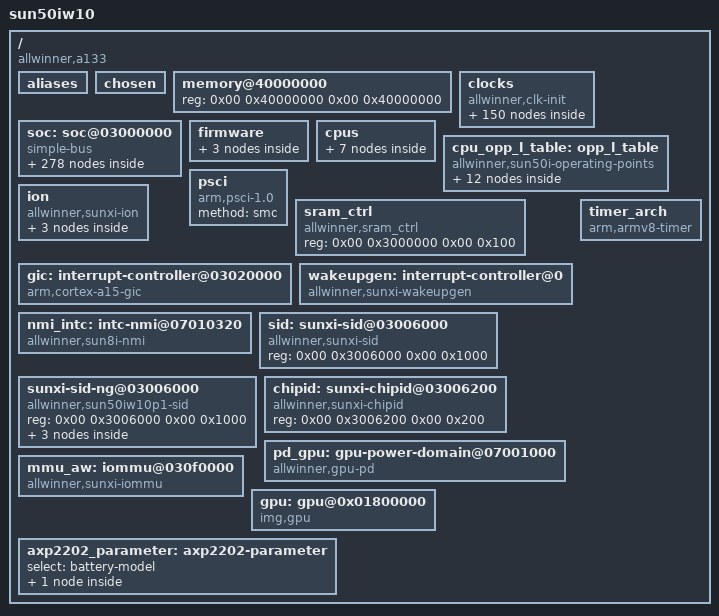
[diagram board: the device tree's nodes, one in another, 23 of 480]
/*
 * The TrimUI Brick (Allwinner A133P): its device tree, as source.
 *
 * Made from the tree TrimUI's system boots the Brick with (their DTB,
 * decompiled), with what our system doesn't use taken out: TrimUI's boot
 * loader leftovers, their userspace's settings, USB host, and the rest that
 * carapace's make-dt.py removed. The labels are TrimUI's (Allwinner's names,
 * from the tree's __symbols__). Each node keeps its phandle number from that
 * tree, so a reference still written as a number points where it did.
 *
 * The nodes U-Boot looks up by path when it boots Linux (/aliases, /chosen,
 * the memory) come first among the root's nodes: U-Boot walks every node ahead
 * of the one it wants, and with /aliases behind soc that was 104 ms of the
 * boot (2026-10-12).
 */
/dts-v1/;

/memreserve/	0x0000000048000000 0x0000000001000000;
/memreserve/	0x0000000048100000 0x0000000000100000;
/memreserve/	0x0000000042000000 0x000000000000000c;
/memreserve/	0x000000007b81f480 0x0000000000300000;
/memreserve/	0x0000000040000000 0x0000000000040000;
/memreserve/	0x0000000049e78000 0x000000000018796f;
/ {
	serial-number = "54408000c335a81b";
	model = "sun50iw10";
	compatible = "allwinner,a133\0arm,sun50iw10p1";
	interrupt-parent = <&wakeupgen>;
	#address-cells = <0x02>;
	#size-cells = <0x02>;

	aliases {
		serial0 = "/soc@03000000/uart@05000000\0/soc@03000000/uart@05000000";
		serial1 = "/soc@03000000/uart@05000400\0/soc@03000000/uart@05000400";
		serial2 = "/soc@03000000/uart@05000800\0/soc@03000000/uart@05000800";
		serial3 = "/soc@03000000/uart@05000c00\0/soc@03000000/uart@05000c00";
		serial4 = "/soc@03000000/uart@05001000\0/soc@03000000/uart@05001000";
		serial5 = "/soc@03000000/uart@05001400\0/soc@03000000/uart@05001400";
		serial6 = "/soc@03000000/uart@05001800\0/soc@03000000/uart@05001800";
		serial7 = "/soc@03000000/uart@07080000\0/soc@03000000/uart@07080000";
		ir0 = "/soc@03000000/s_cir@07040000\0/soc@03000000/s_cir@07040000";
		ir1 = "/soc@03000000/ir@0x05071000\0/soc@03000000/ir@0x05071000";
		twi0 = "/soc@03000000/twi@0x05002000\0/soc@03000000/twi@0x05002000";
		twi1 = "/soc@03000000/twi@0x05002400\0/soc@03000000/twi@0x05002400";
		twi2 = "/soc@03000000/twi@0x05002800\0/soc@03000000/twi@0x05002800";
		twi3 = "/soc@03000000/twi@0x05002c00\0/soc@03000000/twi@0x05002c00";
		twi4 = "/soc@03000000/twi@0x05003000\0/soc@03000000/twi@0x05003000";
		twi5 = "/soc@03000000/twi@0x05003400\0/soc@03000000/twi@0x05003400";
		twi6 = "/soc@03000000/s_twi@0x07081400\0/soc@03000000/s_twi@0x07081400";
		twi7 = "/soc@03000000/s_twi@0x07081800\0/soc@03000000/s_twi@0x07081800";
		spi0 = "/soc@03000000/spi@05010000\0/soc@03000000/spi@05010000";
		spi1 = "/soc@03000000/spi@05011000\0/soc@03000000/spi@05011000";
		spi2 = "/soc@03000000/spi@05012000\0/soc@03000000/spi@05012000";
		ledc = "/soc@03000000/ledc@0x05018000\0/soc@03000000/ledc@0x05018000";
		pcie = "/soc@03000000/pcie@0x05400000\0/soc@03000000/pcie@0x05400000";
		gmac0 = "/soc@03000000/eth@05020000\0/soc@03000000/eth@05020000";
		gmac1 = "/soc@03000000/eth@05030000\0/soc@03000000/eth@05030000";
		global_timer0 = "/soc@03000000/timer@03009000\0/soc@03000000/timer@03009000";
		mmc0 = "/soc@03000000/sdmmc@04020000\0/soc@03000000/sdmmc@04020000";
		mmc2 = "/soc@03000000/sdmmc@04022000\0/soc@03000000/sdmmc@04022000";
		nand0 = "/soc@03000000/nand0@04011000\0/soc@03000000/nand0@04011000";
		disp = "/soc@03000000/disp@06000000\0/soc@03000000/disp@06000000";
		eink = "/soc@03000000/eink@06400000\0/soc@03000000/eink@06400000";
		tps65185 = "/soc@03000000/tps65185@68\0/soc@03000000/tps65185@68";
		tps65185_slave = "/soc@03000000/tps65185_slave@68\0/soc@03000000/tps65185_slave@68";
		lcd0 = "/soc@03000000/lcd0@01c0c000\0/soc@03000000/lcd0@01c0c000";
		lcd1 = "/soc@03000000/lcd1@01c0c001\0/soc@03000000/lcd1@01c0c001";
		pwm = "/soc@03000000/pwm@0300a000\0/soc@03000000/pwm@0300a000";
		pwm0 = "/soc@03000000/pwm0@0300a000\0/soc@03000000/pwm0@0300a000";
		pwm1 = "/soc@03000000/pwm1@0300a000\0/soc@03000000/pwm1@0300a000";
		pwm2 = "/soc@03000000/pwm2@0300a000\0/soc@03000000/pwm2@0300a000";
		pwm3 = "/soc@03000000/pwm3@0300a000\0/soc@03000000/pwm3@0300a000";
		pwm4 = "/soc@03000000/pwm4@0300a000\0/soc@03000000/pwm4@0300a000";
		pwm5 = "/soc@03000000/pwm5@0300a000\0/soc@03000000/pwm5@0300a000";
		pwm6 = "/soc@03000000/pwm6@0300a000\0/soc@03000000/pwm6@0300a000";
		pwm7 = "/soc@03000000/pwm7@0300a000\0/soc@03000000/pwm7@0300a000";
		pwm8 = "/soc@03000000/pwm8@0300a000\0/soc@03000000/pwm8@0300a000";
		pwm9 = "/soc@03000000/pwm9@0300a000\0/soc@03000000/pwm9@0300a000";
		pwm10 = "/soc@03000000/pwm10@0300a000\0/soc@03000000/pwm10@0300a000";
		pwm11 = "/soc@03000000/pwm11@0300a000\0/soc@03000000/pwm11@0300a000";
		pwm12 = "/soc@03000000/pwm12@0300a000\0/soc@03000000/pwm12@0300a000";
		pwm13 = "/soc@03000000/pwm13@0300a000\0/soc@03000000/pwm13@0300a000";
		pwm14 = "/soc@03000000/pwm14@0300a000\0/soc@03000000/pwm14@0300a000";
		pwm15 = "/soc@03000000/pwm15@0300a000\0/soc@03000000/pwm15@0300a000";
		ac200 = "/soc@03000000/ac200\0/soc@03000000/ac200";
		boot_disp = "/soc@03000000/boot_disp\0/soc@03000000/boot_disp";
		pmu0 = "/soc@03000000/s_twi@0x07081400/pmu@34\0/soc@03000000/s_twi@0x07081400/pmu@34";
		standby_param = "/soc@03000000/standby_param\0/soc@03000000/standby_param";
	};

	chosen {
		smbios3-entrypoint = <0x00 0x7bf47000>;
		u-boot,version = "2026.10-g5124c9daeafe";
		bootargs = "console=ttyS0,115200 loglevel=1 rdinit=/rdinit cma=64M";
		linux,initrd-start = <0x00 0x49e78000>;
		linux,initrd-end = <0x00 0x49fff96f>;
	};

	memory@40000000 {
		device_type = "memory";
		reg = <0x00 0x40000000 0x00 0x40000000>;
	};

	clocks {
		compatible = "allwinner,clk-init";
		device_type = "clocks";
		#address-cells = <0x02>;
		#size-cells = <0x02>;
		ranges;
		reg = <0x00 0x3001000 0x00 0x1000 0x00 0x7010000 0x00 0x400 0x00 0x7000000 0x00 0x04>;

		clk_losc: losc {
			#clock-cells = <0x00>;
			compatible = "allwinner,fixed-clock";
			clock-frequency = <0x8000>;
			clock-output-names = "losc";
			phandle = <0x18>;
		};

		clk_iosc: iosc {
			#clock-cells = <0x00>;
			compatible = "allwinner,fixed-clock";
			clock-frequency = <0xf42400>;
			clock-output-names = "iosc";
			phandle = <0x1d>;
		};

		clk_hosc: hosc {
			#clock-cells = <0x00>;
			compatible = "allwinner,fixed-clock";
			clock-frequency = <0x16e3600>;
			clock-output-names = "hosc";
			phandle = <0x0a>;
		};

		clk_osc48m: osc48m {
			#clock-cells = <0x00>;
			compatible = "allwinner,fixed-clock";
			clock-frequency = <0x2dc6c00>;
			clock-output-names = "osc48m";
			phandle = <0x0b>;
		};

		clk_hoscdiv32k: hoscdiv32k {
			#clock-cells = <0x00>;
			compatible = "allwinner,fixed-clock";
			clock-frequency = <0x8000>;
			clock-output-names = "hoscdiv32k";
			phandle = <0x10a>;
		};

		clk_ext_32k: ext_32k {
			#clock-cells = <0x00>;
			compatible = "allwinner,fixed-clock";
			clock-frequency = <0x8000>;
			clock-output-names = "ext_32k";
			phandle = <0x10b>;
		};

		clk_pll_periph0div25m: pll_periph0div25m {
			#clock-cells = <0x00>;
			compatible = "allwinner,fixed-clock";
			clock-frequency = <0x17d7840>;
			clock-output-names = "pll_periph0div25m";
			phandle = <0x10c>;
		};

		clk_pll_cpu: pll_cpu {
			#clock-cells = <0x00>;
			compatible = "allwinner,pll-clock";
			lock-mode = "new";
			clock-output-names = "pll_cpu";
			phandle = <0xfe>;
		};

		clk_pll_ddr: pll_ddr {
			#clock-cells = <0x00>;
			compatible = "allwinner,pll-clock";
			lock-mode = "new";
			clock-output-names = "pll_ddr";
			phandle = <0x1b>;
		};

		clk_pll_periph0: pll_periph0 {
			#clock-cells = <0x00>;
			compatible = "allwinner,pll-clock";
			assigned-clock-rates = <0x23c34600>;
			lock-mode = "new";
			clock-output-names = "pll_periph0";
			phandle = <0x06>;
		};

		clk_pll_periph1: pll_periph1 {
			#clock-cells = <0x00>;
			compatible = "allwinner,pll-clock";
			assigned-clock-rates = <0x23c34600>;
			lock-mode = "new";
			clock-output-names = "pll_periph1";
			phandle = <0x07>;
		};

		clk_pll_gpu: pll_gpu {
			#clock-cells = <0x00>;
			compatible = "allwinner,pll-clock";
			lock-mode = "new";
			clock-output-names = "pll_gpu";
			phandle = <0x107>;
		};

		clk_pll_video0x4: pll_video0x4 {
			#clock-cells = <0x00>;
			compatible = "allwinner,pll-clock";
			lock-mode = "new";
			clock-output-names = "pll_video0x4";
			phandle = <0x08>;
		};

		clk_pll_video1x4: pll_video1x4 {
			#clock-cells = <0x00>;
			compatible = "allwinner,pll-clock";
			lock-mode = "new";
			clock-output-names = "pll_video1x4";
			phandle = <0x09>;
		};

		clk_pll_video2: pll_video2 {
			#clock-cells = <0x00>;
			compatible = "allwinner,pll-clock";
			lock-mode = "new";
			assigned-clocks = <&clk_pll_video2>;
			assigned-clock-rates = <0x1406f400>;
			clock-output-names = "pll_video2";
			phandle = <0x02>;
		};

		clk_pll_video3: pll_video3 {
			#clock-cells = <0x00>;
			compatible = "allwinner,pll-clock";
			lock-mode = "new";
			assigned-clocks = <&clk_pll_video3>;
			assigned-clock-rates = <0x11e1a300>;
			clock-output-names = "pll_video3";
			phandle = <0x03>;
		};

		clk_pll_ve: pll_ve {
			#clock-cells = <0x00>;
			compatible = "allwinner,pll-clock";
			device_type = "clk_pll_ve";
			lock-mode = "new";
			clock-output-names = "pll_ve";
			phandle = <0x24>;
		};

		clk_pll_com: pll_com {
			#clock-cells = <0x00>;
			compatible = "allwinner,pll-clock";
			assigned-clocks = <&clk_pll_com>;
			assigned-clock-rates = <0x23c34600>;
			lock-mode = "new";
			clock-output-names = "pll_com";
			phandle = <0x04>;
		};

		clk_pll_audiox4: pll_audiox4 {
			#clock-cells = <0x00>;
			compatible = "allwinner,pll-clock";
			assigned-clocks = <&clk_pll_audiox4>;
			assigned-clock-rates = <0x5dc0000>;
			lock-mode = "new";
			clock-output-names = "pll_audiox4";
			phandle = <0x05>;
		};

		clk_pll_periph0x2: pll_periph0x2 {
			#clock-cells = <0x00>;
			compatible = "allwinner,fixed-factor-clock";
			clocks = <&clk_pll_periph0>;
			clock-mult = <0x02>;
			clock-div = <0x01>;
			clock-output-names = "pll_periph0x2";
			phandle = <0x0c>;
		};

		clk_pll_periph0x4: pll_periph0x4 {
			#clock-cells = <0x00>;
			compatible = "allwinner,fixed-factor-clock";
			clocks = <&clk_pll_periph0>;
			clock-mult = <0x04>;
			clock-div = <0x01>;
			clock-output-names = "pll_periph0x4";
			phandle = <0x10d>;
		};

		clk_periph32k: periph32k {
			#clock-cells = <0x00>;
			compatible = "allwinner,fixed-factor-clock";
			clocks = <&clk_pll_periph0>;
			clock-mult = <0x02>;
			clock-div = <0x8f0d>;
			clock-output-names = "periph32k";
			phandle = <0x10e>;
		};

		clk_pll_periph1x2: pll_periph1x2 {
			#clock-cells = <0x00>;
			compatible = "allwinner,fixed-factor-clock";
			clocks = <&clk_pll_periph1>;
			clock-mult = <0x02>;
			clock-div = <0x01>;
			clock-output-names = "pll_periph1x2";
			phandle = <0xa9>;
		};

		clk_pll_comdiv5: pll_comdiv5 {
			#clock-cells = <0x00>;
			compatible = "allwinner,fixed-factor-clock";
			clocks = <&clk_pll_com>;
			clock-mult = <0x01>;
			clock-div = <0x05>;
			clock-output-names = "pll_comdiv5";
			phandle = <0x7d>;
		};

		clk_pll_audiox8: pll_audiox8 {
			#clock-cells = <0x00>;
			compatible = "allwinner,fixed-factor-clock";
			clocks = <&clk_pll_audiox4>;
			clock-mult = <0x02>;
			clock-div = <0x01>;
			clock-output-names = "pll_audiox8";
			phandle = <0x10f>;
		};

		clk_pll_audio: pll_audio {
			#clock-cells = <0x00>;
			compatible = "allwinner,fixed-factor-clock";
			clocks = <&clk_pll_audiox4>;
			clock-mult = <0x01>;
			clock-div = <0x04>;
			clock-output-names = "pll_audio";
			phandle = <0x80>;
		};

		clk_pll_audiox2: pll_audiox2 {
			#clock-cells = <0x00>;
			compatible = "allwinner,fixed-factor-clock";
			clocks = <&clk_pll_audiox4>;
			clock-mult = <0x01>;
			clock-div = <0x02>;
			clock-output-names = "pll_audiox2";
			phandle = <0x110>;
		};

		clk_pll_video0: pll_video0 {
			#clock-cells = <0x00>;
			compatible = "allwinner,fixed-factor-clock";
			clocks = <&clk_pll_video0x4>;
			clock-mult = <0x01>;
			clock-div = <0x04>;
			clock-output-names = "pll_video0";
			phandle = <0x111>;
		};

		clk_pll_video0x2: pll_video0x2 {
			#clock-cells = <0x00>;
			compatible = "allwinner,fixed-factor-clock";
			clocks = <&clk_pll_video0x4>;
			clock-mult = <0x01>;
			clock-div = <0x02>;
			clock-output-names = "pll_video0x2";
			phandle = <0x112>;
		};

		clk_pll_video1: pll_video1 {
			#clock-cells = <0x00>;
			compatible = "allwinner,fixed-factor-clock";
			clocks = <&clk_pll_video1x4>;
			clock-mult = <0x01>;
			clock-div = <0x04>;
			clock-output-names = "pll_video1";
			phandle = <0x113>;
		};

		clk_pll_video1x2: pll_video1x2 {
			#clock-cells = <0x00>;
			compatible = "allwinner,fixed-factor-clock";
			clocks = <&clk_pll_video1x4>;
			clock-mult = <0x01>;
			clock-div = <0x02>;
			clock-output-names = "pll_video1x2";
			phandle = <0x114>;
		};

		clk_pll_video2x2: pll_video2x2 {
			#clock-cells = <0x00>;
			compatible = "allwinner,fixed-factor-clock";
			clocks = <&clk_pll_video2>;
			clock-mult = <0x02>;
			clock-div = <0x01>;
			clock-output-names = "pll_video2x2";
			phandle = <0xdc>;
		};

		clk_pll_video2x4: pll_video2x4 {
			#clock-cells = <0x00>;
			compatible = "allwinner,fixed-factor-clock";
			clocks = <&clk_pll_video2>;
			clock-mult = <0x04>;
			clock-div = <0x01>;
			clock-output-names = "pll_video2x4";
			phandle = <0x115>;
		};

		clk_pll_video3x2: pll_video3x2 {
			#clock-cells = <0x00>;
			compatible = "allwinner,fixed-factor-clock";
			clocks = <&clk_pll_video3>;
			clock-mult = <0x02>;
			clock-div = <0x01>;
			clock-output-names = "pll_video3x2";
			phandle = <0xe0>;
		};

		clk_pll_video3x4: pll_video3x4 {
			#clock-cells = <0x00>;
			compatible = "allwinner,fixed-factor-clock";
			clocks = <&clk_pll_video3>;
			clock-mult = <0x04>;
			clock-div = <0x01>;
			clock-output-names = "pll_video3x4";
			phandle = <0x116>;
		};

		clk_hoscd2: hoscd2 {
			#clock-cells = <0x00>;
			compatible = "allwinner,fixed-factor-clock";
			clocks = <&clk_hosc>;
			clock-mult = <0x01>;
			clock-div = <0x02>;
			clock-output-names = "hoscd2";
			phandle = <0x117>;
		};

		clk_osc48md4: osc48md4 {
			#clock-cells = <0x00>;
			compatible = "allwinner,fixed-factor-clock";
			clocks = <&clk_osc48m>;
			clock-mult = <0x01>;
			clock-div = <0x04>;
			clock-output-names = "osc48md4";
			phandle = <0x7a>;
		};

		clk_pll_periph0d6: pll_periph0d6 {
			#clock-cells = <0x00>;
			compatible = "allwinner,fixed-factor-clock";
			clocks = <&clk_pll_periph0>;
			clock-mult = <0x01>;
			clock-div = <0x06>;
			clock-output-names = "pll_periph0d6";
			phandle = <0x118>;
		};

		clk_cpu: cpu {
			#clock-cells = <0x00>;
			compatible = "allwinner,cpu-clock";
			clock-output-names = "cpu";
			phandle = <0x119>;
		};

		clk_axi: axi {
			#clock-cells = <0x00>;
			compatible = "allwinner,periph-clock";
			clock-output-names = "axi";
			phandle = <0x11a>;
		};

		clk_cpuapb: cpuapb {
			#clock-cells = <0x00>;
			compatible = "allwinner,periph-clock";
			clock-output-names = "cpuapb";
			phandle = <0xa5>;
		};

		clk_psi: psi {
			#clock-cells = <0x00>;
			compatible = "allwinner,periph-clock";
			clock-output-names = "psi";
			phandle = <0x11b>;
		};

		clk_ahb1: ahb1 {
			#clock-cells = <0x00>;
			compatible = "allwinner,periph-clock";
			clock-output-names = "ahb1";
			phandle = <0x11c>;
		};

		clk_ahb2: ahb2 {
			#clock-cells = <0x00>;
			compatible = "allwinner,periph-clock";
			clock-output-names = "ahb2";
			phandle = <0x11d>;
		};

		clk_ahb3: ahb3 {
			#clock-cells = <0x00>;
			compatible = "allwinner,periph-clock";
			clock-output-names = "ahb3";
			phandle = <0x11e>;
		};

		clk_apb1: apb1 {
			#clock-cells = <0x00>;
			compatible = "allwinner,periph-clock";
			clock-output-names = "apb1";
			phandle = <0x11f>;
		};

		clk_apb2: apb2 {
			#clock-cells = <0x00>;
			compatible = "allwinner,periph-clock";
			clock-output-names = "apb2";
			phandle = <0x120>;
		};

		clk_mbus: mbus {
			#clock-cells = <0x00>;
			compatible = "allwinner,periph-clock";
			clock-output-names = "mbus";
			phandle = <0x1c>;
		};

		clk_de0: de0 {
			#clock-cells = <0x00>;
			compatible = "allwinner,periph-clock";
			assigned-clock-parents = <&clk_pll_periph0x2>;
			assigned-clock-rates = <0x11e1a300>;
			assigned-clocks = <&clk_de0>;
			clock-output-names = "de0";
			phandle = <0x0d>;
		};

		clk_de1: de1 {
			#clock-cells = <0x00>;
			compatible = "allwinner,periph-clock";
			assigned-clock-parents = <&clk_pll_periph0x2>;
			assigned-clock-rates = <0x11e1a300>;
			assigned-clocks = <&clk_de1>;
			clock-output-names = "de1";
			phandle = <0x0e>;
		};

		clk_g2d: g2d {
			#clock-cells = <0x00>;
			compatible = "allwinner,periph-clock";
			clock-output-names = "g2d";
			assigned-clock-parents = <&clk_pll_periph0x2>;
			assigned-clock-rates = <0x11e1a300>;
			assigned-clocks = <&clk_g2d>;
			phandle = <0x0f>;
		};

		clk_ee: ee {
			#clock-cells = <0x00>;
			compatible = "allwinner,periph-clock";
			assigned-clock-parents = <&clk_pll_periph0x2>;
			assigned-clock-rates = <0x11e1a300>;
			assigned-clocks = <&clk_ee>;
			clock-output-names = "ee";
			phandle = <0x10>;
		};

		clk_panel: panel {
			#clock-cells = <0x00>;
			compatible = "allwinner,periph-clock";
			assigned-clock-parents = <&clk_pll_video2>;
			assigned-clock-rates = <0x1c9c380>;
			assigned-clocks = <&clk_panel>;
			clock-output-names = "panel";
			phandle = <0x11>;
		};

		clk_gpu: gpu {
			#clock-cells = <0x00>;
			compatible = "allwinner,periph-clock";
			clock-output-names = "gpu";
			phandle = <0x108>;
		};

		clk_ce: ce {
			#clock-cells = <0x00>;
			compatible = "allwinner,periph-clock";
			clock-output-names = "ce";
			phandle = <0xe8>;
		};

		clk_ve: ve {
			#clock-cells = <0x00>;
			compatible = "allwinner,periph-clock";
			clock-output-names = "ve";
			phandle = <0x25>;
		};

		clk_dma: dma {
			#clock-cells = <0x00>;
			compatible = "allwinner,periph-clock";
			clock-output-names = "dma";
			phandle = <0x1a>;
		};

		clk_msgbox: msgbox {
			#clock-cells = <0x00>;
			compatible = "allwinner,periph-clock";
			clock-output-names = "msgbox";
			phandle = <0x1e>;
		};

		clk_hwspinlock_rst: hwspinlock_rst {
			#clock-cells = <0x00>;
			compatible = "allwinner,periph-clock";
			clock-output-names = "hwspinlock_rst";
			phandle = <0x121>;
		};

		clk_hwspinlock_bus: hwspinlock_bus {
			#clock-cells = <0x00>;
			compatible = "allwinner,periph-clock";
			clock-output-names = "hwspinlock_bus";
			phandle = <0x122>;
		};

		clk_hstimer: hstimer {
			#clock-cells = <0x00>;
			compatible = "allwinner,periph-clock";
			clock-output-names = "hstimer";
			phandle = <0x123>;
		};

		clk_avs: avs {
			#clock-cells = <0x00>;
			compatible = "allwinner,periph-clock";
			clock-output-names = "avs";
			phandle = <0x124>;
		};

		clk_dbgsys: dbgsys {
			#clock-cells = <0x00>;
			compatible = "allwinner,periph-clock";
			clock-output-names = "dbgsys";
			phandle = <0x125>;
		};

		clk_pwm: pwm {
			#clock-cells = <0x00>;
			compatible = "allwinner,periph-clock";
			clock-output-names = "pwm";
			phandle = <0xc4>;
		};

		clk_spwm: spwm {
			#clock-cells = <0x00>;
			compatible = "allwinner,periph-cpus-clock";
			clock-output-names = "spwm";
			phandle = <0xd5>;
		};

		clk_iommu: iommu {
			#clock-cells = <0x00>;
			compatible = "allwinner,periph-clock";
			clock-output-names = "iommu";
			phandle = <0x106>;
		};

		clk_sdram: sdram {
			#clock-cells = <0x00>;
			compatible = "allwinner,periph-clock";
			clock-output-names = "sdram";
			phandle = <0x126>;
		};

		clk_nand0: nand0 {
			#clock-cells = <0x00>;
			compatible = "allwinner,periph-clock";
			clock-output-names = "nand0";
			phandle = <0xe9>;
		};

		clk_nand1: nand1 {
			#clock-cells = <0x00>;
			compatible = "allwinner,periph-clock";
			clock-output-names = "nand1";
			phandle = <0xea>;
		};

		clk_sdmmc0_mod: sdmmc0_mod {
			#clock-cells = <0x00>;
			compatible = "allwinner,periph-clock";
			clock-output-names = "sdmmc0_mod";
			phandle = <0xb0>;
		};

		clk_sdmmc0_bus: sdmmc0_bus {
			#clock-cells = <0x00>;
			compatible = "allwinner,periph-clock";
			clock-output-names = "sdmmc0_bus";
			phandle = <0xb1>;
		};

		clk_sdmmc0_rst: sdmmc0_rst {
			#clock-cells = <0x00>;
			compatible = "allwinner,periph-clock";
			clock-output-names = "sdmmc0_rst";
			phandle = <0xb2>;
		};

		clk_sdmmc1_mod: sdmmc1_mod {
			#clock-cells = <0x00>;
			compatible = "allwinner,periph-clock";
			clock-output-names = "sdmmc1_mod";
			phandle = <0xb6>;
		};

		clk_sdmmc1_bus: sdmmc1_bus {
			#clock-cells = <0x00>;
			compatible = "allwinner,periph-clock";
			clock-output-names = "sdmmc1_bus";
			phandle = <0xb7>;
		};

		clk_sdmmc1_rst: sdmmc1_rst {
			#clock-cells = <0x00>;
			compatible = "allwinner,periph-clock";
			clock-output-names = "sdmmc1_rst";
			phandle = <0xb8>;
		};

		clk_sdmmc2_mod: sdmmc2_mod {
			#clock-cells = <0x00>;
			compatible = "allwinner,periph-clock";
			clock-output-names = "sdmmc2_mod";
			phandle = <0xaa>;
		};

		clk_sdmmc2_bus: sdmmc2_bus {
			#clock-cells = <0x00>;
			compatible = "allwinner,periph-clock";
			clock-output-names = "sdmmc2_bus";
			phandle = <0xab>;
		};

		clk_sdmmc2_rst: sdmmc2_rst {
			#clock-cells = <0x00>;
			compatible = "allwinner,periph-clock";
			clock-output-names = "sdmmc2_rst";
			phandle = <0xac>;
		};

		clk_uart0: uart0 {
			#clock-cells = <0x00>;
			compatible = "allwinner,periph-clock";
			clock-output-names = "uart0";
			phandle = <0x27>;
		};

		clk_uart1: uart1 {
			#clock-cells = <0x00>;
			compatible = "allwinner,periph-clock";
			clock-output-names = "uart1";
			phandle = <0x2b>;
		};

		clk_uart2: uart2 {
			#clock-cells = <0x00>;
			compatible = "allwinner,periph-clock";
			clock-output-names = "uart2";
			phandle = <0x2e>;
		};

		clk_uart3: uart3 {
			#clock-cells = <0x00>;
			compatible = "allwinner,periph-clock";
			clock-output-names = "uart3";
			phandle = <0x31>;
		};

		clk_uart4: uart4 {
			#clock-cells = <0x00>;
			compatible = "allwinner,periph-clock";
			clock-output-names = "uart4";
			phandle = <0x34>;
		};

		clk_uart5: uart5 {
			#clock-cells = <0x00>;
			compatible = "allwinner,periph-clock";
			clock-output-names = "uart5";
			phandle = <0x37>;
		};

		clk_uart6: uart6 {
			#clock-cells = <0x00>;
			compatible = "allwinner,periph-clock";
			clock-output-names = "uart6";
			phandle = <0x3a>;
		};

		clk_twi0: twi0 {
			#clock-cells = <0x00>;
			compatible = "allwinner,periph-clock";
			clock-output-names = "twi0";
			phandle = <0x5b>;
		};

		clk_twi1: twi1 {
			#clock-cells = <0x00>;
			compatible = "allwinner,periph-clock";
			clock-output-names = "twi1";
			phandle = <0x5e>;
		};

		clk_stwi0: stwi0 {
			#clock-cells = <0x00>;
			compatible = "allwinner,periph-cpus-clock";
			clock-output-names = "stwi0";
			phandle = <0x40>;
		};

		clk_stwi1: stwi1 {
			#clock-cells = <0x00>;
			compatible = "allwinner,periph-cpus-clock";
			clock-output-names = "stwi1";
			phandle = <0x6e>;
		};

		clk_twi2: twi2 {
			#clock-cells = <0x00>;
			compatible = "allwinner,periph-clock";
			clock-output-names = "twi2";
			phandle = <0x62>;
		};

		clk_twi3: twi3 {
			#clock-cells = <0x00>;
			compatible = "allwinner,periph-clock";
			clock-output-names = "twi3";
			phandle = <0x65>;
		};

		clk_twi4: twi4 {
			#clock-cells = <0x00>;
			compatible = "allwinner,periph-clock";
			clock-output-names = "twi4";
			phandle = <0x68>;
		};

		clk_twi5: twi5 {
			#clock-cells = <0x00>;
			compatible = "allwinner,periph-clock";
			clock-output-names = "twi5";
			phandle = <0x6b>;
		};

		clk_scr0: scr0 {
			#clock-cells = <0x00>;
			compatible = "allwinner,periph-clock";
			clock-output-names = "scr0";
			phandle = <0x127>;
		};

		clk_spi0: spi0 {
			#clock-cells = <0x00>;
			compatible = "allwinner,periph-clock";
			clock-output-names = "spi0";
			phandle = <0x99>;
		};

		clk_spi1: spi1 {
			#clock-cells = <0x00>;
			compatible = "allwinner,periph-clock";
			clock-output-names = "spi1";
			phandle = <0x9d>;
		};

		clk_spi2: spi2 {
			#clock-cells = <0x00>;
			compatible = "allwinner,periph-clock";
			clock-output-names = "spi2";
			phandle = <0xa0>;
		};

		clk_gmac0_25m: gmac0_25m {
			#clock-cells = <0x00>;
			compatible = "allwinner,periph-clock";
			clock-output-names = "gmac0_25m";
			phandle = <0xf6>;
		};

		clk_gmac1_25m: gmac1_25m {
			#clock-cells = <0x00>;
			compatible = "allwinner,periph-clock";
			clock-output-names = "gmac1_25m";
			phandle = <0xfa>;
		};

		clk_gmac0: gmac0 {
			#clock-cells = <0x00>;
			compatible = "allwinner,periph-clock";
			clock-output-names = "gmac0";
			phandle = <0xf5>;
		};

		clk_gmac1: gmac1 {
			#clock-cells = <0x00>;
			compatible = "allwinner,periph-clock";
			clock-output-names = "gmac1";
			phandle = <0xf9>;
		};

		clk_gpadc: gpadc {
			#clock-cells = <0x00>;
			compatible = "allwinner,periph-clock";
			clock-output-names = "gpadc";
			phandle = <0xf3>;
		};

		clk_irtx: irtx {
			#clock-cells = <0x00>;
			compatible = "allwinner,periph-clock";
			clock-output-names = "irtx";
			phandle = <0x22>;
		};

		clk_ths: ths {
			#clock-cells = <0x00>;
			compatible = "allwinner,periph-clock";
			clock-output-names = "ths";
			phandle = <0xee>;
		};

		clk_i2s0: i2s0 {
			#clock-cells = <0x00>;
			compatible = "allwinner,periph-clock";
			clock-output-names = "i2s0";
			phandle = <0x89>;
		};

		clk_i2s1: i2s1 {
			#clock-cells = <0x00>;
			compatible = "allwinner,periph-clock";
			clock-output-names = "i2s1";
			phandle = <0x8d>;
		};

		clk_i2s2: i2s2 {
			#clock-cells = <0x00>;
			compatible = "allwinner,periph-clock";
			clock-output-names = "i2s2";
			phandle = <0x91>;
		};

		clk_i2s3: i2s3 {
			#clock-cells = <0x00>;
			compatible = "allwinner,periph-clock";
			clock-output-names = "i2s3";
			phandle = <0x95>;
		};

		clk_spdif: spdif {
			#clock-cells = <0x00>;
			compatible = "allwinner,periph-clock";
			clock-output-names = "spdif";
			phandle = <0x81>;
		};

		clk_dmic: dmic {
			#clock-cells = <0x00>;
			compatible = "allwinner,periph-clock";
			clock-output-names = "dmic";
			phandle = <0x85>;
		};

		clk_codec_dac_1x: codec_dac_1x {
			#clock-cells = <0x00>;
			compatible = "allwinner,periph-clock";
			clock-output-names = "codec_dac_1x";
			phandle = <0x7b>;
		};

		clk_codec_adc_1x: codec_adc_1x {
			#clock-cells = <0x00>;
			compatible = "allwinner,periph-clock";
			clock-output-names = "codec_adc_1x";
			phandle = <0x7c>;
		};

		clk_codec_4x: codec_4x {
			#clock-cells = <0x00>;
			compatible = "allwinner,periph-clock";
			clock-output-names = "codec_4x";
			phandle = <0x128>;
		};

		clk_usbphy0: usbphy0 {
			#clock-cells = <0x00>;
			compatible = "allwinner,periph-clock";
			clock-output-names = "usbphy0";
			phandle = <0x71>;
		};

		clk_usbphy1: usbphy1 {
			#clock-cells = <0x00>;
			compatible = "allwinner,periph-clock";
			clock-output-names = "usbphy1";
			phandle = <0x74>;
		};

		clk_usbohci0: usbohci0 {
			#clock-cells = <0x00>;
			compatible = "allwinner,periph-clock";
			clock-output-names = "usbohci0";
			phandle = <0x76>;
		};

		clk_usbohci0_12m: usbohci0_12m {
			#clock-cells = <0x00>;
			compatible = "allwinner,periph-clock";
			clock-output-names = "usbohci0_12m";
			phandle = <0x129>;
		};

		clk_usbohci1: usbohci1 {
			#clock-cells = <0x00>;
			compatible = "allwinner,periph-clock";
			clock-output-names = "usbohci1";
			phandle = <0x77>;
		};

		clk_usbohci1_12m: usbohci1_12m {
			#clock-cells = <0x00>;
			compatible = "allwinner,periph-clock";
			clock-output-names = "usbohci1_12m";
			phandle = <0x79>;
		};

		clk_usbehci0: usbehci0 {
			#clock-cells = <0x00>;
			compatible = "allwinner,periph-clock";
			clock-output-names = "usbehci0";
			phandle = <0x75>;
		};

		clk_usbehci1: usbehci1 {
			#clock-cells = <0x00>;
			compatible = "allwinner,periph-clock";
			clock-output-names = "usbehci1";
			phandle = <0x73>;
		};

		clk_usbotg: usbotg {
			#clock-cells = <0x00>;
			compatible = "allwinner,periph-clock";
			clock-output-names = "usbotg";
			phandle = <0x72>;
		};

		clk_display_top: display_top {
			#clock-cells = <0x00>;
			compatible = "allwinner,periph-clock";
			clock-output-names = "display_top";
			phandle = <0xbd>;
		};

		clk_dpss_top0: dpss_top0 {
			#clock-cells = <0x00>;
			compatible = "allwinner,periph-clock";
			clock-output-names = "dpss_top0";
			phandle = <0xbe>;
		};

		clk_dpss_top1: dpss_top1 {
			#clock-cells = <0x00>;
			compatible = "allwinner,periph-clock";
			clock-output-names = "dpss_top1";
			phandle = <0xbf>;
		};

		clk_tcon_lcd0: tcon_lcd0 {
			#clock-cells = <0x00>;
			compatible = "allwinner,periph-clock";
			clock-output-names = "tcon_lcd0";
			assigned-clocks = <&clk_tcon_lcd0>;
			assigned-clock-parents = <&clk_pll_video0x4>;
			phandle = <0x12>;
		};

		clk_tcon_lcd1: tcon_lcd1 {
			#clock-cells = <0x00>;
			compatible = "allwinner,periph-clock";
			clock-output-names = "tcon_lcd1";
			assigned-clocks = <&clk_tcon_lcd1>;
			assigned-clock-parents = <&clk_pll_video1x4>;
			phandle = <0x13>;
		};

		clk_lvds: lvds {
			#clock-cells = <0x00>;
			compatible = "allwinner,periph-clock";
			clock-output-names = "lvds";
			phandle = <0xc0>;
		};

		clk_lvds1: lvds1 {
			#clock-cells = <0x00>;
			compatible = "allwinner,periph-clock";
			clock-output-names = "lvds1";
			phandle = <0xc1>;
		};

		clk_mipi_host: mipi_host {
			#clock-cells = <0x00>;
			compatible = "allwinner,periph-clock";
			clock-output-names = "mipi_host";
			assigned-clocks = <&clk_mipi_host>;
			assigned-clock-parents = <&clk_pll_periph0>;
			assigned-clock-rates = <0x8f0d180>;
			phandle = <0x14>;
		};

		clk_csi_top: csi_top {
			#clock-cells = <0x00>;
			compatible = "allwinner,periph-clock";
			clock-output-names = "csi_top";
			phandle = <0xdb>;
		};

		clk_csi_isp: csi_isp {
			#clock-cells = <0x00>;
			compatible = "allwinner,periph-clock";
			clock-output-names = "csi_isp";
			phandle = <0xdf>;
		};

		clk_csi_master0: csi_master0 {
			#clock-cells = <0x00>;
			compatible = "allwinner,periph-clock";
			clock-output-names = "csi_master0";
			phandle = <0xdd>;
		};

		clk_csi_master1: csi_master1 {
			#clock-cells = <0x00>;
			compatible = "allwinner,periph-clock";
			clock-output-names = "csi_master1";
			phandle = <0xde>;
		};

		clk_pio: pio {
			#clock-cells = <0x00>;
			compatible = "allwinner,periph-clock";
			clock-output-names = "pio";
			phandle = <0x19>;
		};

		clk_ledc: ledc {
			#clock-cells = <0x00>;
			compatible = "allwinner,periph-clock";
			clock-output-names = "ledc";
			phandle = <0xa4>;
		};

		clk_cpurcir: cpurcir {
			#clock-cells = <0x00>;
			compatible = "allwinner,periph-cpus-clock";
			clock-output-names = "cpurcir";
			phandle = <0x20>;
		};

		clk_hosc32k: hosc32k {
			#clock-cells = <0x00>;
			compatible = "allwinner,periph-cpus-clock";
			clock-output-names = "hosc32k";
			phandle = <0x15>;
		};

		clk_losc_out: losc_out {
			#clock-cells = <0x00>;
			compatible = "allwinner,periph-cpus-clock";
			assigned-clock-parents = <&clk_hosc32k>;
			assigned-clocks = <&clk_losc_out>;
			clock-output-names = "losc_out";
			phandle = <0x16>;
		};

		clk_cpurcpus_pll: cpurcpus_pll {
			#clock-cells = <0x00>;
			compatible = "allwinner,periph-cpus-clock";
			clock-output-names = "cpurcpus_pll";
			phandle = <0x12a>;
		};

		clk_cpurcpus: cpurcpus {
			#clock-cells = <0x00>;
			compatible = "allwinner,periph-cpus-clock";
			clock-output-names = "cpurcpus";
			phandle = <0x12b>;
		};

		clk_cpurahbs: cpurahbs {
			#clock-cells = <0x00>;
			compatible = "allwinner,periph-cpus-clock";
			clock-output-names = "cpurahbs";
			phandle = <0x12c>;
		};

		clk_cpurapbs1: cpurapbs1 {
			#clock-cells = <0x00>;
			compatible = "allwinner,periph-cpus-clock";
			clock-output-names = "cpurapbs1";
			phandle = <0x12d>;
		};

		clk_cpurapbs2_pll: cpurapbs2_pll {
			#clock-cells = <0x00>;
			compatible = "allwinner,periph-cpus-clock";
			clock-output-names = "cpurapbs2_pll";
			phandle = <0x12e>;
		};

		clk_cpurapbs2: cpurapbs2 {
			#clock-cells = <0x00>;
			compatible = "allwinner,periph-cpus-clock";
			clock-output-names = "cpurapbs2";
			phandle = <0x12f>;
		};

		clk_ppu: ppu {
			#clock-cells = <0x00>;
			compatible = "allwinner,periph-cpus-clock";
			clock-output-names = "ppu";
			phandle = <0x105>;
		};

		clk_cpurpio: cpurpio {
			#clock-cells = <0x00>;
			compatible = "allwinner,periph-cpus-clock";
			clock-output-names = "cpurpio";
			phandle = <0x17>;
		};

		clk_dcxo_out: dcxo_out {
			#clock-cells = <0x00>;
			compatible = "allwinner,periph-cpus-clock";
			clock-output-names = "dcxo_out";
			phandle = <0xfd>;
		};

		clk_suart: suart {
			#clock-cells = <0x00>;
			compatible = "allwinner,periph-cpus-clock";
			clock-output-names = "suart";
			phandle = <0x3d>;
		};

		clk_lradc: lradc {
			#clock-cells = <0x00>;
			compatible = "allwinner,periph-clock";
			clock-output-names = "lradc";
			phandle = <0xf4>;
		};
	};

	soc: soc@03000000 {
		compatible = "simple-bus";
		#address-cells = <0x02>;
		#size-cells = <0x02>;
		ranges;
		device_type = "soc";
		phandle = <0x130>;

		r_pio: pinctrl@07022000 {
			compatible = "allwinner,sun50iw10p1-r-pinctrl";
			reg = <0x00 0x7022000 0x00 0x400>;
			interrupts = <0x00 0x6f 0x04>;
			clocks = <&clk_cpurpio &clk_losc &clk_hosc>;
			device_type = "r_pio";
			gpio-controller;
			interrupt-controller;
			#interrupt-cells = <0x03>;
			#size-cells = <0x00>;
			#gpio-cells = <0x06>;
			input-debounce = <0x00>;
			phandle = <0x61>;

			s_rsb0_pins_a: s_rsb0@0 {
				allwinner,pins = "PL0\0PL1";
				allwinner,function = "s_rsb0";
				allwinner,muxsel = <0x02>;
				allwinner,drive = <0x02>;
				allwinner,pull = <0x01>;
				phandle = <0x131>;
			};

			s_uart0_pins_a: s_uart0@0 {
				allwinner,pins = "PL2\0PL3";
				allwinner,function = "s_uart0";
				allwinner,muxsel = <0x02>;
				allwinner,drive = <0x01>;
				allwinner,pull = <0x01>;
				phandle = <0x3e>;
			};

			s_uart0_pins_b: s_uart0@1 {
				allwinner,pins = "PL2\0PL3";
				allwinner,function = "io_disabled";
				allwinner,muxsel = <0x07>;
				allwinner,drive = <0x01>;
				allwinner,pull = <0x01>;
				phandle = <0x3f>;
			};

			s_twi0_pins_a: s_twi0@0 {
				allwinner,pins = "PL0\0PL1";
				allwinner,pname = "s_twi0_scl\0s_twi0_sda";
				allwinner,function = "s_twi0";
				allwinner,muxsel = <0x02>;
				allwinner,drive = <0x01>;
				allwinner,pull = <0x01>;
				phandle = <0x41>;
			};

			s_twi0_pins_b: s_twi0@1 {
				allwinner,pins = "PL0\0PL1";
				allwinner,function = "gpio_out";
				allwinner,muxsel = <0x01>;
				allwinner,drive = <0x01>;
				allwinner,pull = <0x01>;
				phandle = <0x42>;
			};

			s_twi1_pins_a: s_twi1@0 {
				allwinner,pins = "PL8\0PL9";
				allwinner,pname = "s_twi1_scl\0s_twi1_sda";
				allwinner,function = "s_twi1";
				allwinner,muxsel = <0x02>;
				allwinner,drive = <0x01>;
				allwinner,pull = <0x01>;
				phandle = <0x6f>;
			};

			s_twi1_pins_b: s_twi1@1 {
				allwinner,pins = "PL8\0PL9";
				allwinner,function = "io_disabled";
				allwinner,muxsel = <0x07>;
				allwinner,drive = <0x01>;
				allwinner,pull = <0x00>;
				phandle = <0x70>;
			};

			s_cir0_pins_a: s_cir0@0 {
				allwinner,pins = "PL11";
				allwinner,function = "s_cir0";
				allwinner,muxsel = <0x03>;
				allwinner,drive = <0x01>;
				allwinner,pull = <0x01>;
				phandle = <0x1f>;
			};
		};

		pio: pinctrl@0300b000 {
			compatible = "allwinner,sun50iw10p1-pinctrl";
			reg = <0x00 0x300b000 0x00 0x400>;
			interrupts = <0x00 0x36 0x04 0x00 0x37 0x04 0x00 0x38 0x04 0x00 0x39 0x04 0x00 0x3a 0x04 0x00 0x3b 0x04 0x00 0x3c 0x04 0x00 0x3d 0x04 0x00 0x3e 0x04>;
			device_type = "pio";
			clocks = <&clk_pio &clk_losc &clk_hosc>;
			gpio-controller;
			interrupt-controller;
			#interrupt-cells = <0x03>;
			#size-cells = <0x00>;
			#gpio-cells = <0x06>;
			input-debounce = <0x00 0x00 0x00 0x00 0x00 0x00 0x00 0x00 0x00>;
			phandle = <0x45>;

			vdevice_pins_a: vdevice@0 {
				allwinner,pins = "PB0\0PB1";
				allwinner,function = "Vdevice";
				allwinner,muxsel = <0x05>;
				allwinner,drive = <0x01>;
				allwinner,pull = <0x01>;
				phandle = <0xe7>;
			};

			uart0_pins_b: uart0@1 {
				allwinner,pins = "PB9\0PB10";
				allwinner,function = "uart0";
				allwinner,muxsel = <0x07>;
				allwinner,drive = <0x01>;
				allwinner,pull = <0x00>;
				phandle = <0x29>;
			};

			uart1_pins_a: uart1@0 {
				allwinner,pins = "PG6\0PG7\0PG8\0PG9";
				allwinner,pname = "uart1_tx\0uart1_rx\0uart1_rts\0uart1_cts";
				allwinner,function = "uart1";
				allwinner,muxsel = <0x02>;
				allwinner,drive = <0x01>;
				allwinner,pull = <0x01>;
				phandle = <0x2c>;
			};

			uart1_pins_b: uart1@1 {
				allwinner,pins = "PG6\0PG7\0PG8\0PG9";
				allwinner,function = "io_disabled";
				allwinner,muxsel = <0x07>;
				allwinner,drive = <0x01>;
				allwinner,pull = <0x00>;
				phandle = <0x2d>;
			};

			uart2_pins_a: uart2@0 {
				allwinner,pins = "PB0\0PB1\0PB2\0PB3";
				allwinner,pname = "uart2_tx\0uart2_rx\0uart2_rts\0uart2_cts";
				allwinner,function = "uart2";
				allwinner,muxsel = <0x02>;
				allwinner,drive = <0x01>;
				allwinner,pull = <0x01>;
				phandle = <0x2f>;
			};

			uart2_pins_b: uart2@1 {
				allwinner,pins = "PB0\0PB1\0PB2\0PB3";
				allwinner,function = "io_disabled";
				allwinner,muxsel = <0x07>;
				allwinner,drive = <0x01>;
				allwinner,pull = <0x00>;
				phandle = <0x30>;
			};

			uart3_pins_a: uart3@0 {
				allwinner,pins = "PD15";
				allwinner,pname = "uart3_rx";
				allwinner,function = "uart3";
				allwinner,muxsel = <0x04>;
				allwinner,drive = <0x01>;
				allwinner,pull = <0x01>;
				phandle = <0x32>;
			};

			uart3_pins_b: uart3@1 {
				allwinner,pins = "PD15";
				allwinner,function = "io_disabled";
				allwinner,muxsel = <0x07>;
				allwinner,drive = <0x01>;
				allwinner,pull = <0x00>;
				phandle = <0x33>;
			};

			uart4_pins_a: uart4@0 {
				allwinner,pins = "PD19";
				allwinner,pname = "uart4_rx";
				allwinner,function = "uart4";
				allwinner,muxsel = <0x04>;
				allwinner,drive = <0x01>;
				allwinner,pull = <0x01>;
				phandle = <0x35>;
			};

			uart4_pins_b: uart4@1 {
				allwinner,pins = "PD19";
				allwinner,function = "io_disabled";
				allwinner,muxsel = <0x07>;
				allwinner,drive = <0x01>;
				allwinner,pull = <0x00>;
				phandle = <0x36>;
			};

			uart5_pins_a: uart5@0 {
				allwinner,pins = "PI2\0PI3\0PI4\0PI5";
				allwinner,pname = "uart5_tx\0uart5_rx\0uart5_rts\0uart5_cts";
				allwinner,function = "uart5";
				allwinner,muxsel = <0x02>;
				allwinner,drive = <0x01>;
				allwinner,pull = <0x01>;
				phandle = <0x38>;
			};

			uart5_pins_b: uart5@1 {
				allwinner,pins = "PI2\0PI3\0PI4\0PI5";
				allwinner,function = "io_disabled";
				allwinner,muxsel = <0x07>;
				allwinner,drive = <0x01>;
				allwinner,pull = <0x00>;
				phandle = <0x39>;
			};

			uart6_pins_a: uart6@0 {
				allwinner,pins = "PI6\0PI7\0PI13\0PI14";
				allwinner,pname = "uart6_tx\0uart6_rx\0uart6_rts\0uart6_cts";
				allwinner,function = "uart6";
				allwinner,muxsel = <0x02>;
				allwinner,drive = <0x01>;
				allwinner,pull = <0x01>;
				phandle = <0x3b>;
			};

			uart6_pins_b: uart6@1 {
				allwinner,pins = "PI6\0PI7\0PI13\0PI14";
				allwinner,function = "io_disabled";
				allwinner,muxsel = <0x07>;
				allwinner,drive = <0x01>;
				allwinner,pull = <0x00>;
				phandle = <0x3c>;
			};

			ir0_pins_a: ir0@0 {
				allwinner,pins = "PH3";
				allwinner,pname = "it-tx";
				allwinner,function = "ir0";
				allwinner,muxsel = <0x03>;
				allwinner,drive = <0x01>;
				allwinner,pull = <0x00>;
				phandle = <0x21>;
			};

			ir0_pins_b: ir0@1 {
				allwinner,pins = "PH3";
				allwinner,pname = "io_disabled";
				allwinner,function = "io_disabled";
				allwinner,muxsel = <0x07>;
				allwinner,drive = <0x01>;
				allwinner,pull = <0x00>;
				phandle = <0x23>;
			};

			twi0_pins_a: twi0@0 {
				allwinner,pins = "PH0\0PH1";
				allwinner,pname = "twi0_scl\0twi0_sda";
				allwinner,function = "twi0";
				allwinner,muxsel = <0x02>;
				allwinner,drive = <0x01>;
				allwinner,pull = <0x00>;
				phandle = <0x5c>;
			};

			twi0_pins_b: twi0@1 {
				allwinner,pins = "PH0\0PH1";
				allwinner,function = "io_disabled";
				allwinner,muxsel = <0x07>;
				allwinner,drive = <0x01>;
				allwinner,pull = <0x00>;
				phandle = <0x5d>;
			};

			twi1_pins_a: twi1@0 {
				allwinner,pins = "PH2\0PH3";
				allwinner,pname = "twi1_scl\0twi1_sda";
				allwinner,function = "twi1";
				allwinner,muxsel = <0x02>;
				allwinner,drive = <0x01>;
				allwinner,pull = <0x00>;
				phandle = <0x5f>;
			};

			twi1_pins_b: twi1@1 {
				allwinner,pins = "PH2\0PH3";
				allwinner,function = "io_disabled";
				allwinner,muxsel = <0x07>;
				allwinner,drive = <0x01>;
				allwinner,pull = <0x00>;
				phandle = <0x60>;
			};

			twi2_pins_a: twi2@0 {
				allwinner,pins = "PE1\0PE2";
				allwinner,pname = "twi2_scl\0twi2_sda";
				allwinner,function = "twi2";
				allwinner,muxsel = <0x02>;
				allwinner,drive = <0x01>;
				allwinner,pull = <0x00>;
				phandle = <0x63>;
			};

			twi2_pins_b: twi2@1 {
				allwinner,pins = "PE1\0PE2";
				allwinner,function = "io_disabled";
				allwinner,muxsel = <0x07>;
				allwinner,drive = <0x01>;
				allwinner,pull = <0x00>;
				phandle = <0x64>;
			};

			twi3_pins_a: twi3@0 {
				allwinner,pins = "PH12\0PH13";
				allwinner,pname = "twi3_scl\0twi3_sda";
				allwinner,function = "twi3";
				allwinner,muxsel = <0x03>;
				allwinner,drive = <0x01>;
				allwinner,pull = <0x01>;
				phandle = <0x66>;
			};

			twi3_pins_b: twi3@1 {
				allwinner,pins = "PH12\0PH13";
				allwinner,function = "io_disabled";
				allwinner,muxsel = <0x07>;
				allwinner,drive = <0x01>;
				allwinner,pull = <0x00>;
				phandle = <0x67>;
			};

			twi4_pins_a: twi4@0 {
				allwinner,pins = "PI0\0PI1";
				allwinner,pname = "twi4_scl\0twi4_sda";
				allwinner,function = "twi4";
				allwinner,muxsel = <0x02>;
				allwinner,drive = <0x01>;
				allwinner,pull = <0x00>;
				phandle = <0x69>;
			};

			twi4_pins_b: twi4@1 {
				allwinner,pins = "PI0\0PI1";
				allwinner,function = "io_disabled";
				allwinner,muxsel = <0x07>;
				allwinner,drive = <0x01>;
				allwinner,pull = <0x00>;
				phandle = <0x6a>;
			};

			twi5_pins_a: twi5@0 {
				allwinner,pins = "PI8\0PI9";
				allwinner,pname = "twi5_scl\0twi5_sda";
				allwinner,function = "twi5";
				allwinner,muxsel = <0x02>;
				allwinner,drive = <0x01>;
				allwinner,pull = <0x00>;
				phandle = <0x6c>;
			};

			twi5_pins_b: twi5@1 {
				allwinner,pins = "PI8\0PI9";
				allwinner,function = "io_disabled";
				allwinner,muxsel = <0x07>;
				allwinner,drive = <0x01>;
				allwinner,pull = <0x00>;
				phandle = <0x6d>;
			};

			ts0_pins_a: ts0@0 {
				allwinner,pins = "PD0\0PD1\0PD2\0PD3\0PD4\0PD5\0PD6\0PD7\0PD8\0PD9\0PD10\0PD11";
				allwinner,pname = "ts0_clk\0ts0_err\0ts0_sync\0ts0_dvld\0ts0_d0\0ts0_d1\0ts0_d2\0ts0_d3\0ts0_d4\0ts0_d5\0ts0_d6\0ts0_d7";
				allwinner,function = "ts0";
				allwinner,muxsel = <0x04>;
				allwinner,drive = <0x01>;
				allwinner,pull = <0x00>;
				phandle = <0x132>;
			};

			ts0_pins_b: ts0_sleep@0 {
				allwinner,pins = "PD0\0PD1\0PD2\0PD3\0PD4\0PD5\0PD6\0PD7\0PD8\0PD9\0PD10\0PD11";
				allwinner,pname = "ts0_clk\0ts0_err\0ts0_sync\0ts0_dvld\0ts0_d0\0ts0_d1\0ts0_d2\0ts0_d3\0ts0_d4\0ts0_d5\0ts0_d6\0ts0_d7";
				allwinner,function = "io_disabled";
				allwinner,muxsel = <0x07>;
				allwinner,drive = <0x01>;
				allwinner,pull = <0x00>;
				phandle = <0x133>;
			};

			spi0_pins_a: spi0@0 {
				allwinner,pins = "PC2\0PC4\0PC12\0PC15\0PC16";
				allwinner,pname = "spi0_mosi\0spi0_miso\0spi0_sclk\0spi0_wp\0spi0_hold";
				allwinner,function = "spi0";
				allwinner,muxsel = <0x04>;
				allwinner,drive = <0x01>;
				allwinner,pull = <0x00>;
				phandle = <0x9a>;
			};

			spi0_pins_b: spi0@1 {
				allwinner,pins = "PC3\0PC7";
				allwinner,pname = "spi0_cs0\0spi0_cs1";
				allwinner,function = "spi0";
				allwinner,muxsel = <0x04>;
				allwinner,drive = <0x01>;
				allwinner,pull = <0x01>;
				phandle = <0x9b>;
			};

			spi0_pins_c: spi0@2 {
				allwinner,pins = "PC2\0PC3\0PC4\0PC7\0PC12\0PC15\0PC16";
				allwinner,function = "io_disabled";
				allwinner,muxsel = <0x07>;
				allwinner,drive = <0x01>;
				allwinner,pull = <0x00>;
				phandle = <0x134>;
			};




			spi2_pins_a: spi2@0 {
				allwinner,pins = "PB1\0PB2\0PB3";
				allwinner,pname = "spi2_sclk\0spi2_mosi\0spi2_miso";
				allwinner,function = "spi2";
				allwinner,muxsel = <0x03>;
				allwinner,drive = <0x01>;
				allwinner,pull = <0x00>;
				phandle = <0xa1>;
			};

			spi2_pins_b: spi2@1 {
				allwinner,pins = "PB0";
				allwinner,pname = "spi2_cs0";
				allwinner,function = "spi2";
				allwinner,muxsel = <0x03>;
				allwinner,drive = <0x01>;
				allwinner,pull = <0x01>;
				phandle = <0xa2>;
			};

			spi2_pins_c: spi2@2 {
				allwinner,pins = "PB0\0PB1\0PB2\0PB3";
				allwinner,function = "io_disabled";
				allwinner,muxsel = <0x07>;
				allwinner,drive = <0x01>;
				allwinner,pull = <0x00>;
				phandle = <0xa3>;
			};

			sdc0_pins_a: sdc0@0 {
				allwinner,pins = "PF0\0PF1\0PF2\0PF3\0PF4\0PF5";
				allwinner,function = "sdc0";
				allwinner,muxsel = <0x02>;
				allwinner,drive = <0x03>;
				allwinner,pull = <0x01>;
				phandle = <0xb3>;
			};

			sdc0_pins_b: sdc0@1 {
				allwinner,pins = "PF0\0PF1\0PF2\0PF3\0PF4\0PF5";
				allwinner,function = "io_disabled";
				allwinner,muxsel = <0x07>;
				allwinner,drive = <0x01>;
				allwinner,pull = <0x01>;
				phandle = <0xb4>;
			};

			sdc0_pins_c: sdc0@2 {
				allwinner,pins = "PF0\0PF1\0PF2\0PF3\0PF4\0PF5";
				allwinner,function = "uart0_jtag";
				allwinner,muxsel = <0x03>;
				allwinner,drive = <0x01>;
				allwinner,pull = <0x01>;
				phandle = <0xb5>;
			};

			sdc1_pins_a: sdc1@0 {
				allwinner,pins = "PG0\0PG1\0PG2\0PG3\0PG4\0PG5";
				allwinner,function = "sdc1";
				allwinner,muxsel = <0x02>;
				allwinner,drive = <0x03>;
				allwinner,pull = <0x01>;
				phandle = <0xb9>;
			};

			sdc1_pins_b: sdc1@1 {
				allwinner,pins = "PG0\0PG1\0PG2\0PG3\0PG4\0PG5";
				allwinner,function = "io_disabled";
				allwinner,muxsel = <0x07>;
				allwinner,drive = <0x01>;
				allwinner,pull = <0x01>;
				phandle = <0xba>;
			};

			sdc2_pins_a: sdc2@0 {
				allwinner,pins = "PC1\0PC5\0PC6\0PC8\0PC9\0PC10\0PC11\0PC13\0PC14\0PC15\0PC16";
				allwinner,function = "sdc2";
				allwinner,muxsel = <0x03>;
				allwinner,drive = <0x03>;
				allwinner,pull = <0x01>;
				phandle = <0xad>;
			};

			sdc2_pins_b: sdc2@1 {
				allwinner,pins = "PC0\0PC1\0PC5\0PC6\0PC8\0PC9\0PC10\0PC11\0PC13\0PC14\0PC15\0PC16";
				allwinner,function = "io_disabled";
				allwinner,muxsel = <0x07>;
				allwinner,drive = <0x01>;
				allwinner,pull = <0x01>;
				phandle = <0xaf>;
			};

			sdc2_pins_c: sdc2@2 {
				allwinner,pins = "PC0";
				allwinner,function = "sdc2";
				allwinner,muxsel = <0x03>;
				allwinner,drive = <0x03>;
				allwinner,pull = <0x02>;
				phandle = <0xae>;
			};

			sdc3_pins_a: sdc3@0 {
				allwinner,pins = "PI14\0PI13\0PI12\0PI11\0PI10\0PI9";
				allwinner,function = "sdc3";
				allwinner,muxsel = <0x03>;
				allwinner,drive = <0x02>;
				allwinner,pull = <0x01>;
				phandle = <0xbb>;
			};

			sdc3_pins_b: sdc3@1 {
				allwinner,pins = "PI14\0PI13\0PI12\0PI11\0PI10\0PI9";
				allwinner,function = "io_disabled";
				allwinner,muxsel = <0x07>;
				allwinner,drive = <0x01>;
				allwinner,pull = <0x01>;
				phandle = <0xbc>;
			};

			daudio0_pins_a: daudio0@0 {
				allwinner,pins = "PB4\0PB5\0PB6\0PB7\0PB8";
				allwinner,function = "pcm0";
				allwinner,muxsel = <0x03>;
				allwinner,drive = <0x01>;
				allwinner,pull = <0x00>;
				phandle = <0x8a>;
			};

			daudio0_pins_b: daudio0_sleep@0 {
				allwinner,pins = "PB4\0PB5\0PB6\0PB7\0PB8";
				allwinner,function = "io_disabled";
				allwinner,muxsel = <0x07>;
				allwinner,drive = <0x01>;
				allwinner,pull = <0x00>;
				phandle = <0x8b>;
			};

			daudio1_pins_a: daudio1@0 {
				allwinner,pins = "PG9\0PG10\0PG11\0PG12\0PG13";
				allwinner,function = "pcm1";
				allwinner,muxsel = <0x03>;
				allwinner,drive = <0x01>;
				allwinner,pull = <0x00>;
				phandle = <0x8e>;
			};

			daudio1_pins_b: daudio1_sleep@0 {
				allwinner,pins = "PG9\0PG10\0PG11\0PG12\0PG13";
				allwinner,function = "io_disabled";
				allwinner,muxsel = <0x07>;
				allwinner,drive = <0x01>;
				allwinner,pull = <0x00>;
				phandle = <0x8f>;
			};

			daudio2_pins_a: daudio2@0 {
				allwinner,pins = "PE5\0PE6\0PE7\0PE8\0PE9";
				allwinner,function = "pcm2";
				allwinner,muxsel = <0x04>;
				allwinner,drive = <0x01>;
				allwinner,pull = <0x00>;
				phandle = <0x92>;
			};

			daudio2_pins_b: daudio2_sleep@0 {
				allwinner,pins = "PE5\0PE6\0PE7\0PE8\0PE9";
				allwinner,function = "io_disabled";
				allwinner,muxsel = <0x07>;
				allwinner,drive = <0x01>;
				allwinner,pull = <0x00>;
				phandle = <0x93>;
			};

			daudio3_pins_a: daudio3@0 {
				allwinner,pins = "PH13\0PH14\0PH15\0PH16\0PH17\0PH18\0PH19";
				allwinner,function = "pcm3";
				allwinner,muxsel = <0x04>;
				allwinner,drive = <0x01>;
				allwinner,pull = <0x00>;
				phandle = <0x96>;
			};

			daudio3_pins_b: daudio3_sleep@0 {
				allwinner,pins = "PH13\0PH14\0PH15\0PH16\0PH17\0PH18\0PH19";
				allwinner,function = "io_disabled";
				allwinner,muxsel = <0x07>;
				allwinner,drive = <0x01>;
				allwinner,pull = <0x00>;
				phandle = <0x97>;
			};

			spdif_pins_a: spdif@0 {
				allwinner,pins = "PH6\0PH7";
				allwinner,function = "spdif";
				allwinner,muxsel = <0x04>;
				allwinner,drive = <0x01>;
				allwinner,pull = <0x00>;
				phandle = <0x82>;
			};

			spdif_pins_b: spdif_sleep@0 {
				allwinner,pins = "PH6\0PH7";
				allwinner,function = "io_disabled";
				allwinner,muxsel = <0x07>;
				allwinner,drive = <0x01>;
				allwinner,pull = <0x00>;
				phandle = <0x83>;
			};

			dmic_pins_a: dmic@0 {
				allwinner,pins = "PH8\0PH9\0PH10\0PH11\0PH12";
				allwinner,function = "dmic";
				allwinner,muxsel = <0x02>;
				allwinner,drive = <0x01>;
				allwinner,pull = <0x00>;
				phandle = <0x86>;
			};

			dmic_pins_b: dmic_sleep@0 {
				allwinner,pins = "PH8\0PH9\0PH10\0PH11\0PH12";
				allwinner,function = "io_disabled";
				allwinner,muxsel = <0x07>;
				allwinner,drive = <0x01>;
				allwinner,pull = <0x00>;
				phandle = <0x87>;
			};

			csi_mclk0_pins_a: csi_mclk0@0 {
				allwinner,pins = "PE0";
				allwinner,pname = "csi_mclk0";
				allwinner,function = "csi_mclk0";
				allwinner,muxsel = <0x02>;
				allwinner,drive = <0x02>;
				allwinner,pull = <0x00>;
				phandle = <0xe1>;
			};

			csi_mclk0_pins_b: csi_mclk0@1 {
				allwinner,pins = "PE0";
				allwinner,pname = "csi_mclk0";
				allwinner,function = "io_disabled";
				allwinner,muxsel = <0x07>;
				allwinner,drive = <0x02>;
				allwinner,pull = <0x00>;
				phandle = <0xe2>;
			};

			csi_mclk1_pins_a: csi_mclk1@0 {
				allwinner,pins = "PE5";
				allwinner,pname = "csi_mclk1";
				allwinner,function = "csi_mclk1";
				allwinner,muxsel = <0x02>;
				allwinner,drive = <0x02>;
				allwinner,pull = <0x00>;
				phandle = <0xe3>;
			};

			csi_mclk1_pins_b: csi_mclk1@1 {
				allwinner,pins = "PE5";
				allwinner,pname = "csi_mclk1";
				allwinner,function = "io_disabled";
				allwinner,muxsel = <0x07>;
				allwinner,drive = <0x02>;
				allwinner,pull = <0x00>;
				phandle = <0xe4>;
			};

			scr0_pins_a: scr0@0 {
				allwinner,pins = "PG13\0PG14\0PG10\0PG11\0PG12";
				allwinner,pname = "scr0_rst\0scr0_det\0scr0_vccen\0scr0_sck\0scr0_sda";
				allwinner,function = "sim0";
				allwinner,muxsel = <0x04>;
				allwinner,drive = <0x00>;
				allwinner,pull = <0x01>;
				phandle = <0x135>;
			};

			scr0_pins_b: scr0@1 {
				allwinner,pins = "PG8\0PG9";
				allwinner,pname = "scr0_vppen\0scr0_vppp";
				allwinner,function = "sim0";
				allwinner,muxsel = <0x04>;
				allwinner,drive = <0x00>;
				allwinner,pull = <0x01>;
				phandle = <0x136>;
			};

			scr0_pins_c: scr0@2 {
				allwinner,pins = "PG8\0PG9\0PG10\0PG11\0PG12\0PG13\0PG14";
				allwinner,function = "io_disabled";
				allwinner,muxsel = <0x07>;
				allwinner,drive = <0x00>;
				allwinner,pull = <0x00>;
				phandle = <0x137>;
			};

			scr1_pins_a: scr1@0 {
				allwinner,pins = "PH5\0PH6\0PH2\0PH3\0PH4";
				allwinner,pname = "scr1_rst\0scr1_det\0scr1_vccen\0scr1_sck\0scr1_sda";
				allwinner,function = "sim1";
				allwinner,muxsel = <0x05>;
				allwinner,drive = <0x01>;
				allwinner,pull = <0x01>;
				phandle = <0x138>;
			};

			scr1_pins_b: scr1@1 {
				allwinner,pins = "PH0\0PH1";
				allwinner,pname = "scr1_vppen\0scr1_vppp";
				allwinner,function = "sim1";
				allwinner,muxsel = <0x05>;
				allwinner,drive = <0x01>;
				allwinner,pull = <0x01>;
				phandle = <0x139>;
			};

			scr1_pins_c: scr1@2 {
				allwinner,pins = "PH0\0PH1\0PH2\0PH3\0PH4\0PH5\0PH6";
				allwinner,function = "io_disabled";
				allwinner,muxsel = <0x07>;
				allwinner,drive = <0x01>;
				allwinner,pull = <0x00>;
				phandle = <0x13a>;
			};

			nand0_pins_c: nand0@2 {
				allwinner,pins = "PC0\0PC1\0PC2\0PC3\0PC4\0PC5\0PC6\0PC7\0PC8\0PC9\0PC10\0PC11\0PC12\0PC13\0PC14\0PC15\0PC16";
				allwinner,function = "io_disabled";
				allwinner,muxsel = <0x07>;
				allwinner,drive = <0x01>;
				allwinner,pull = <0x00>;
				phandle = <0xed>;
			};

			ccir_clk_pin_a: ac200@2 {
				allwinner,pins = "PB0";
				allwinner,function = "ac200";
				allwinner,muxsel = <0x02>;
				allwinner,drive = <0x01>;
				allwinner,pull = <0x00>;
				phandle = <0xd9>;
			};

			ccir_clk_pin_b: ac200@3 {
				allwinner,pins = "PB0";
				allwinner,function = "io_disabled";
				allwinner,muxsel = <0x07>;
				allwinner,drive = <0x01>;
				allwinner,pull = <0x00>;
				phandle = <0xda>;
			};

			gmac_pins_a: gmac@0 {
				allwinner,pins = "PH0\0PH1\0PH2\0PH3\0PH4\0PH5\0PH6\0PH7\0PH9\0PH10\0PH13\0PH14\0PH15\0PH16\0PH17\0PH18";
				allwinner,function = "gmac0";
				allwinner,muxsel = <0x05>;
				allwinner,drive = <0x03>;
				allwinner,pull = <0x00>;
				phandle = <0xf7>;
			};

			gmac_pins_b: gmac@1 {
				allwinner,pins = "PH0\0PH1\0PH2\0PH3\0PH4\0PH5\0PH6\0PH7\0PH9\0PH10\0PH13\0PH14\0PH15\0PH16\0PH17\0PH18";
				allwinner,function = "io_disabled";
				allwinner,muxsel = <0x07>;
				allwinner,drive = <0x03>;
				allwinner,pull = <0x00>;
				phandle = <0xf8>;
			};

			gmac1_pins_a: gmac1@0 {
				allwinner,pins = "PJ0\0PJ1\0PJ2\0PJ3\0PJ4\0PJ5\0PJ6\0PJ7\0PJ8\0PJ9\0PJ10\0PJ11\0PJ12\0PJ13\0PJ14\0PJ15";
				allwinner,function = "gmac1";
				allwinner,muxsel = <0x05>;
				allwinner,drive = <0x03>;
				allwinner,pull = <0x00>;
				phandle = <0xfb>;
			};

			gmac1_pins_b: gmac1@1 {
				allwinner,pins = "PJ0\0PJ1\0PJ2\0PJ3\0PJ4\0PJ5\0PJ6\0PJ7\0PJ8\0PJ9\0PJ10\0PJ11\0PJ12\0PJ13\0PJ14\0PJ15";
				allwinner,function = "io_disabled";
				allwinner,muxsel = <0x07>;
				allwinner,drive = <0x03>;
				allwinner,pull = <0x00>;
				phandle = <0xfc>;
			};

			ledc_pins_a: ledc@0 {
				allwinner,pins = "PE5";
				allwinner,function = "ledc";
				allwinner,muxsel = <0x05>;
				allwinner,drive = <0x01>;
				allwinner,pull = <0x01>;
				phandle = <0xa6>;
			};

			ledc_pins_b: ledc@1 {
				allwinner,pins = "PE5";
				allwinner,function = "io_disabled";
				allwinner,muxsel = <0x07>;
				allwinner,drive = <0x01>;
				allwinner,pull = <0x00>;
				phandle = <0xa7>;
			};

			lvds0_pins_a: lvds0@0 {
				allwinner,pins = "PD0\0PD1\0PD2\0PD3\0PD4\0PD5\0PD8\0PD9\0PD6\0PD7";
				allwinner,pname = "PD0\0PD1\0PD2\0PD3\0PD4\0PD5\0PD8\0PD9\0PD6\0PD7";
				allwinner,function = "lvds0";
				allwinner,muxsel = <0x03>;
				allwinner,drive = <0x03>;
				allwinner,pull = <0x00>;
				phandle = <0x13b>;
			};

			lvds0_pins_b: lvds0@1 {
				allwinner,pins = "PD0\0PD1\0PD2\0PD3\0PD4\0PD5\0PD8\0PD9\0PD6\0PD7";
				allwinner,pname = "PD0\0PD1\0PD2\0PD3\0PD4\0PD5\0PD8\0PD9\0PD6\0PD7";
				allwinner,function = "lvds0_suspend";
				allwinner,muxsel = <0x07>;
				allwinner,drive = <0x03>;
				allwinner,pull = <0x00>;
				phandle = <0x13c>;
			};

			lvds1_pins_a: lvds1@0 {
				allwinner,pins = "PD10\0PD11\0PD12\0PD13\0PD14\0PD15\0PD18\0PD19\0PD16\0PD17";
				allwinner,pname = "PD10\0PD11\0PD12\0PD13\0PD14\0PD15\0PD18\0PD19\0PD16\0PD17";
				allwinner,function = "lvds1";
				allwinner,muxsel = <0x03>;
				allwinner,drive = <0x03>;
				allwinner,pull = <0x00>;
				phandle = <0x13d>;
			};

			lvds1_pins_b: lvds1@1 {
				allwinner,pins = "PD10\0PD11\0PD12\0PD13\0PD14\0PD15\0PD18\0PD19\0PD16\0PD17";
				allwinner,pname = "PD10\0PD11\0PD12\0PD13\0PD14\0PD15\0PD18\0PD19\0PD16\0PD17";
				allwinner,function = "lvds1_suspend";
				allwinner,muxsel = <0x07>;
				allwinner,drive = <0x03>;
				allwinner,pull = <0x00>;
				phandle = <0x13e>;
			};

			lvds2_pins_a: lvds2@0 {
				allwinner,pins = "PJ7\0PJ6\0PJ5\0PJ4\0PJ3\0PJ2\0PJ1\0PJ0\0PJ8\0PJ9";
				allwinner,pname = "PJ7\0PJ6\0PJ5\0PJ4\0PJ3\0PJ2\0PJ1\0PJ0\0PJ8\0PJ9";
				allwinner,function = "lvds2";
				allwinner,muxsel = <0x03>;
				allwinner,drive = <0x03>;
				allwinner,pull = <0x00>;
				phandle = <0x13f>;
			};

			lvds2_pins_b: lvds2@1 {
				allwinner,pins = "PJ7\0PJ6\0PJ5\0PJ4\0PJ3\0PJ2\0PJ1\0PJ0\0PJ8\0PJ9";
				allwinner,pname = "PJ7\0PJ6\0PJ5\0PJ4\0PJ3\0PJ2\0PJ1\0PJ0\0PJ8\0PJ9";
				allwinner,function = "lvds2_suspend";
				allwinner,muxsel = <0x07>;
				allwinner,drive = <0x03>;
				allwinner,pull = <0x00>;
				phandle = <0x140>;
			};

			lvds3_pins_a: lvds3@0 {
				allwinner,pins = "PJ10\0PJ11\0PJ12\0PJ13\0PJ14\0PJ15\0PJ16\0PJ17\0PJ18\0PJ19";
				allwinner,pname = "PJ10\0PJ11\0PJ12\0PJ13\0PJ14\0PJ15\0PJ16\0PJ17\0PJ18\0PJ19";
				allwinner,function = "lvds3";
				allwinner,muxsel = <0x03>;
				allwinner,drive = <0x03>;
				allwinner,pull = <0x00>;
				phandle = <0x141>;
			};

			lvds3_pins_b: lvds3@1 {
				allwinner,pins = "PJ10\0PJ11\0PJ12\0PJ13\0PJ14\0PJ15\0PJ16\0PJ17\0PJ18\0PJ19";
				allwinner,pname = "PJ10\0PJ11\0PJ12\0PJ13\0PJ14\0PJ15\0PJ16\0PJ17\0PJ18\0PJ19";
				allwinner,function = "lvds3_suspend";
				allwinner,muxsel = <0x07>;
				allwinner,drive = <0x03>;
				allwinner,pull = <0x00>;
				phandle = <0x142>;
			};

			lcd1_lvds2link_pins_a: lcd1_lvds2link@0 {
				allwinner,pins = "PJ10\0PJ11\0PJ12\0PJ13\0PJ14\0PJ15\0PJ16\0PJ17\0PJ18\0PJ19\0PJ7\0PJ6\0PJ5\0PJ4\0PJ3\0PJ2\0PJ1\0PJ0\0PJ8\0PJ9";
				allwinner,pname = "PJ10\0PJ11\0PJ12\0PJ13\0PJ14\0PJ15\0PJ16\0PJ17\0PJ18\0PJ19\0PJ7\0PJ6\0PJ5\0PJ4\0PJ3\0PJ2\0PJ1\0PJ0\0PJ8\0PJ9";
				allwinner,function = "lvds3";
				allwinner,muxsel = <0x03>;
				allwinner,drive = <0x03>;
				allwinner,pull = <0x00>;
				phandle = <0x143>;
			};

			lcd1_lvds2link_pins_b: lcd1_lvds2link@1 {
				allwinner,pins = "PJ10\0PJ11\0PJ12\0PJ13\0PJ14\0PJ15\0PJ16\0PJ17\0PJ18\0PJ19\0PJ7\0PJ6\0PJ5\0PJ4\0PJ3\0PJ2\0PJ1\0PJ0\0PJ8\0PJ9";
				allwinner,pname = "PJ10\0PJ11\0PJ12\0PJ13\0PJ14\0PJ15\0PJ16\0PJ17\0PJ18\0PJ19\0PJ7\0PJ6\0PJ5\0PJ4\0PJ3\0PJ2\0PJ1\0PJ0\0PJ8\0PJ9";
				allwinner,function = "lvds3_suspend";
				allwinner,muxsel = <0x07>;
				allwinner,drive = <0x03>;
				allwinner,pull = <0x00>;
				phandle = <0x144>;
			};

			lvds2link_pins_a: lvds2link@0 {
				allwinner,pins = "PD0\0PD1\0PD2\0PD3\0PD4\0PD5\0PD8\0PD9\0PD6\0PD7\0PD10\0PD11\0PD12\0PD13\0PD14\0PD15\0PD18\0PD19\0PD16\0PD17";
				allwinner,pname = "PD0\0PD1\0PD2\0PD3\0PD4\0PD5\0PD8\0PD9\0PD6\0PD7\0PD10\0PD11\0PD12\0PD13\0PD14\0PD15\0PD18\0PD19\0PD16\0PD17";
				allwinner,function = "lvds2link";
				allwinner,muxsel = <0x03>;
				allwinner,drive = <0x03>;
				allwinner,pull = <0x00>;
				phandle = <0x145>;
			};

			lvds2link_pins_b: lvds2link@1 {
				allwinner,pins = "PD0\0PD1\0PD2\0PD3\0PD4\0PD5\0PD8\0PD9\0PD6\0PD7\0PD10\0PD11\0PD12\0PD13\0PD14\0PD15\0PD18\0PD19\0PD16\0PD17";
				allwinner,pname = "PD0\0PD1\0PD2\0PD3\0PD4\0PD5\0PD8\0PD9\0PD6\0PD7\0PD10\0PD11\0PD12\0PD13\0PD14\0PD15\0PD18\0PD19\0PD16\0PD17";
				allwinner,function = "lvds2link_suspend";
				allwinner,muxsel = <0x07>;
				allwinner,drive = <0x03>;
				allwinner,pull = <0x00>;
				phandle = <0x146>;
			};

			rgb24_pins_a: rgb24@0 {
				allwinner,pins = "PD0\0PD1\0PD2\0PD3\0PD4\0PD5\0PD6\0PD7\0PD8\0PD9\0PD10\0PD11\0PD12\0PD13\0PD14\0PD15\0PD16\0PD17\0PD18\0PD19\0PD20\0PD21\0PD22\0PD23\0PD24\0PD25\0PD26\0PD27";
				allwinner,pname = "PD0\0PD1\0PD2\0PD3\0PD4\0PD5\0PD6\0PD7\0PD8\0PD9\0PD10\0PD11\0PD12\0PD13\0PD14\0PD15\0PD16\0PD17\0PD18\0PD19\0PD20\0PD21\0PD22\0PD23\0PD24\0PD25\0PD26\0PD27";
				allwinner,function = "rgb24";
				allwinner,muxsel = <0x02>;
				allwinner,drive = <0x03>;
				allwinner,pull = <0x00>;
				phandle = <0x147>;
			};

			rgb24_pins_b: rgb24@1 {
				allwinner,pins = "PD0\0PD1\0PD2\0PD3\0PD4\0PD5\0PD6\0PD7\0PD8\0PD9\0PD10\0PD11\0PD12\0PD13\0PD14\0PD15\0PD16\0PD17\0PD18\0PD19\0PD20\0PD21\0PD22\0PD23\0PD24\0PD25\0PD26\0PD27";
				allwinner,pname = "PD0\0PD1\0PD2\0PD3\0PD4\0PD5\0PD6\0PD7\0PD8\0PD9\0PD10\0PD11\0PD12\0PD13\0PD14\0PD15\0PD16\0PD17\0PD18\0PD19\0PD20\0PD21\0PD22\0PD23\0PD24\0PD25\0PD26\0PD27";
				allwinner,function = "rgb24_suspend";
				allwinner,muxsel = <0x07>;
				allwinner,drive = <0x03>;
				allwinner,pull = <0x00>;
				phandle = <0x148>;
			};

			rgb18_pins_a: rgb18@0 {
				allwinner,pins = "PD0\0PD1\0PD2\0PD3\0PD4\0PD5\0PD6\0PD7\0PD8\0PD9\0PD10\0PD11\0PD12\0PD13\0PD14\0PD15\0PD16\0PD17\0PD18\0PD19\0PD20\0PD21";
				allwinner,pname = "PD0\0PD1\0PD2\0PD3\0PD4\0PD5\0PD6\0PD7\0PD8\0PD9\0PD10\0PD11\0PD12\0PD13\0PD14\0PD15\0PD16\0PD17\0PD18\0PD19\0PD20\0PD21";
				allwinner,function = "rgb18";
				allwinner,muxsel = <0x02>;
				allwinner,drive = <0x03>;
				allwinner,pull = <0x00>;
				phandle = <0x149>;
			};

			rgb18_pins_b: rgb18@1 {
				allwinner,pins = "PD0\0PD1\0PD2\0PD3\0PD4\0PD5\0PD6\0PD7\0PD8\0PD9\0PD10\0PD11\0PD12\0PD13\0PD14\0PD15\0PD16\0PD17\0PD18\0PD19\0PD20\0PD21";
				allwinner,pname = "PD0\0PD1\0PD2\0PD3\0PD4\0PD5\0PD6\0PD7\0PD8\0PD9\0PD10\0PD11\0PD12\0PD13\0PD14\0PD15\0PD16\0PD17\0PD18\0PD19\0PD20\0PD21";
				allwinner,function = "rgb18_suspend";
				allwinner,muxsel = <0x07>;
				allwinner,drive = <0x01>;
				allwinner,pull = <0x00>;
				phandle = <0x14a>;
			};

			eink_pins_a: eink@0 {
				allwinner,pins = "PD0\0PD1\0PD2\0PD3\0PD4\0PD5\0PD6\0PD7\0PD8\0PD9\0PD10\0PD11\0PD12\0PD13\0PD14\0PD15\0PD16\0PD17\0PD18\0PD19\0PD20\0PD21\0PD22";
				allwinner,pname = "eink_pin0\0eink_pin1\0eink_pin2\0eink_pin3\0eink_pin4\0eink_pin5\0eink_pin6\0eink_pin7\0eink_pin8\0eink_pin9\0eink_pin10\0eink_pin11\0eink_pin12\0eink_pin13\0eink_pin14\0eink_pin15\0eink_pinoeh\0eink_pinleh\0eink_pinckh\0eink_pinsth\0eink_pinckv\0eink_pinmod\0eink_pinstv";
				allwinner,function = "eink";
				allwinner,muxsel = <0x05>;
				allwinner,drive = <0x03>;
				allwinner,pull = <0x00>;
				phandle = <0x14b>;
			};

			eink_pins_b: eink@1 {
				allwinner,pins = "PD0\0PD1\0PD2\0PD3\0PD4\0PD5\0PD6\0PD7\0PD8\0PD9\0PD10\0PD11\0PD12\0PD13\0PD14\0PD15\0PD16\0PD17\0PD18\0PD19\0PD20\0PD21\0PD22";
				allwinner,pname = "eink_pin0\0eink_pin1\0eink_pin2\0eink_pin3\0eink_pin4\0eink_pin5\0eink_pin6\0eink_pin7\0eink_pin8\0eink_pin9\0eink_pin10\0eink_pin11\0eink_pin12\0eink_pin13\0eink_pin14\0eink_pin15\0eink_pinoeh\0eink_pinleh\0eink_pinckh\0eink_pinsth\0eink_pinckv\0eink_pinmod\0eink_pinstv";
				allwinner,function = "eink_suspend";
				allwinner,muxsel = <0x07>;
				allwinner,drive = <0x01>;
				allwinner,pull = <0x00>;
				phandle = <0x14c>;
			};

			dsi4lane_pins_a: dsi4lane@0 {
				allwinner,pins = "PD0\0PD1\0PD2\0PD3\0PD4\0PD5\0PD6\0PD7\0PD8\0PD9";
				allwinner,pname = "PD0\0PD1\0PD2\0PD3\0PD4\0PD5\0PD6\0PD7\0PD8\0PD9";
				allwinner,function = "dsi4lane";
				allwinner,muxsel = <0x04>;
				allwinner,drive = <0x03>;
				allwinner,pull = <0x00>;
				phandle = <0xc2>;
			};

			dsi4lane_pins_b: dsi4lane@1 {
				allwinner,pins = "PD0\0PD1\0PD2\0PD3\0PD4\0PD5\0PD6\0PD7\0PD8\0PD9";
				allwinner,pname = "PD0\0PD1\0PD2\0PD3\0PD4\0PD5\0PD6\0PD7\0PD8\0PD9";
				allwinner,function = "dsi4lane_suspend";
				allwinner,muxsel = <0x07>;
				allwinner,drive = <0x01>;
				allwinner,pull = <0x00>;
				phandle = <0xc3>;
			};

			pwm0_pin_a: pwm0@0 {
				allwinner,pins = "PD23";
				allwinner,function = "pwm0";
				allwinner,muxsel = <0x02>;
				allwinner,drive = <0x02>;
				allwinner,pull = <0x00>;
				allwinner,data = <0xffffffff>;
				phandle = <0xd7>;
			};

			pwm0_pin_b: pwm0@1 {
				allwinner,pins = "PD23";
				allwinner,function = "io_disabled";
				allwinner,muxsel = <0x07>;
				allwinner,drive = <0x02>;
				allwinner,pull = <0x00>;
				allwinner,data = <0xffffffff>;
				phandle = <0xd8>;
			};

			pwm1_pin_a: pwm1@0 {
				allwinner,pins = "PD22";
				allwinner,function = "pwm1";
				allwinner,muxsel = <0x02>;
				allwinner,drive = <0x02>;
				allwinner,pull = <0x00>;
				allwinner,data = <0xffffffff>;
				phandle = <0x14d>;
			};

			pwm1_pin_b: pwm1@1 {
				allwinner,pins = "PD22";
				allwinner,function = "io_disabled";
				allwinner,muxsel = <0x07>;
				allwinner,drive = <0x02>;
				allwinner,pull = <0x00>;
				allwinner,data = <0xffffffff>;
				phandle = <0x14e>;
			};

			pwm2_pin_a: pwm2@0 {
				allwinner,pins = "PD20";
				allwinner,function = "pwm2";
				allwinner,muxsel = <0x02>;
				allwinner,drive = <0x02>;
				allwinner,pull = <0x00>;
				allwinner,data = <0xffffffff>;
				phandle = <0x14f>;
			};

			pwm2_pin_b: pwm2@1 {
				allwinner,pins = "PD20";
				allwinner,function = "io_disabled";
				allwinner,muxsel = <0x07>;
				allwinner,drive = <0x02>;
				allwinner,pull = <0x00>;
				allwinner,data = <0xffffffff>;
				phandle = <0x150>;
			};

			pwm3_pin_a: pwm3@0 {
				allwinner,pins = "PD21";
				allwinner,function = "pwm3";
				allwinner,muxsel = <0x02>;
				allwinner,drive = <0x02>;
				allwinner,pull = <0x00>;
				allwinner,data = <0xffffffff>;
				phandle = <0x151>;
			};

			pwm3_pin_b: pwm3@1 {
				allwinner,pins = "PD21";
				allwinner,function = "io_disabled";
				allwinner,muxsel = <0x07>;
				allwinner,drive = <0x02>;
				allwinner,pull = <0x00>;
				allwinner,data = <0xffffffff>;
				phandle = <0x152>;
			};

			card0_boot_para@0 {
				phandle = <0x1c1>;
				allwinner,pins = "PF0\0PF1\0PF2\0PF3\0PF4\0PF5";
				allwinner,function = "card0_boot_para";
				allwinner,pname = "sdc_d1\0sdc_d0\0sdc_clk\0sdc_cmd\0sdc_d3\0sdc_d2";
				allwinner,muxsel = <0x02>;
				allwinner,pull = <0x01>;
				allwinner,drive = <0x03>;
				allwinner,data = <0xffffffff>;
			};

			card2_boot_para@0 {
				phandle = <0x1c2>;
				allwinner,pins = "PC5\0PC6\0PC10\0PC13\0PC15\0PC8\0PC9\0PC11\0PC14\0PC16\0PC1";
				allwinner,function = "card2_boot_para";
				allwinner,pname = "sdc_clk\0sdc_cmd\0sdc_d0\0sdc_d1\0sdc_d2\0sdc_d3\0sdc_d4\0sdc_d5\0sdc_d6\0sdc_d7\0sdc_emmc_rst";
				allwinner,muxsel = <0x03>;
				allwinner,pull = <0x01>;
				allwinner,drive = <0x03>;
				allwinner,data = <0xffffffff>;
			};

			card2_boot_para@1 {
				phandle = <0x1c3>;
				allwinner,pins = "PC0";
				allwinner,function = "card2_boot_para";
				allwinner,pname = "sdc_ds";
				allwinner,muxsel = <0x03>;
				allwinner,pull = <0x02>;
				allwinner,drive = <0x03>;
				allwinner,data = <0xffffffff>;
			};

			uart_para@0 {
				phandle = <0x1c4>;
				allwinner,pins = "PB9\0PB10";
				allwinner,function = "uart_para";
				allwinner,pname = "uart_debug_tx\0uart_debug_rx";
				allwinner,muxsel = <0x02>;
				allwinner,pull = <0x01>;
				allwinner,drive = <0xffffffff>;
				allwinner,data = <0xffffffff>;
			};

			jtag_para@0 {
				phandle = <0x1c5>;
				allwinner,pins = "PH9\0PH10\0PH11\0PH12";
				allwinner,function = "jtag_para";
				allwinner,pname = "jtag_ms\0jtag_ck\0jtag_do\0jtag_di";
				allwinner,muxsel = <0x03>;
				allwinner,pull = <0xffffffff>;
				allwinner,drive = <0xffffffff>;
				allwinner,data = <0xffffffff>;
			};

			uart0_pins_a: uart0@0 {
				phandle = <0x1c6>;
				allwinner,pins = "PB9\0PB10";
				allwinner,function = "uart0";
				allwinner,pname = "uart0_tx\0uart0_rx";
				allwinner,muxsel = <0x02>;
				allwinner,pull = <0x01>;
				allwinner,drive = <0xffffffff>;
				allwinner,data = <0xffffffff>;
			};

			nand0_pins_a: nand0@0 {
				phandle = <0x1c7>;
				allwinner,pins = "PC0\0PC1\0PC2\0PC4\0PC6\0PC7\0PC8\0PC9\0PC10\0PC11\0PC12\0PC13\0PC14";
				allwinner,function = "nand0";
				allwinner,pname = "nand0_we\0nand0_ale\0nand0_cle\0nand0_nre\0nand0_d0\0nand0_d1\0nand0_d2\0nand0_d3\0nand0_d4\0nand0_d5\0nand0_d6\0nand0_d7\0nand0_ndqs";
				allwinner,muxsel = <0x02>;
				allwinner,pull = <0x00>;
				allwinner,drive = <0x01>;
				allwinner,data = <0xffffffff>;
			};

			nand0_pins_b: nand0@1 {
				phandle = <0x1c8>;
				allwinner,pins = "PC3\0PC5\0PC15\0PC16";
				allwinner,function = "nand0";
				allwinner,pname = "nand0_ce0\0nand0_rb0\0nand0_ce1\0nand0_rb1";
				allwinner,muxsel = <0x02>;
				allwinner,pull = <0x01>;
				allwinner,drive = <0x01>;
				allwinner,data = <0xffffffff>;
			};
		};


		dma0: dma-controller@03002000 {
			compatible = "allwinner,sun50i-dma";
			reg = <0x00 0x3002000 0x00 0x1000>;
			interrupts = <0x00 0x2d 0x04>;
			clocks = <&clk_dma>;
			#dma-cells = <0x01>;
			phandle = <0x153>;
		};

		nsi0: nsi-controller@03100000 {
			compatible = "allwinner,sun50i-nsi";
			interrupts = <0x00 0x3f 0x04>;
			reg = <0x00 0x3100000 0x00 0x10000>;
			clocks = <&clk_pll_ddr &clk_mbus>;
			clock-frequency = <0x1ab3f000>;
			#nsi-cells = <0x01>;
			status = "okay";
			phandle = <0x154>;

			cpu {
				/* 1, as TrimUI's boot0 leaves it on their running system, where their
				 * tree says 0: at 0 the display misses its reads under load (broken
				 * rows, the DSI error counter climbing); at 1 it doesn't, measured
				 * 2026-10-12: 175 errors in 904 frames, then none */
				select = <0x01>;
			};

			gpu {
				select = <0x01>;
			};



		};








		soc_timer0: timer@03009000 {
			compatible = "allwinner,sun4i-a10-timer";
			device_type = "soc_timer";
			reg = <0x00 0x3009000 0x00 0x400>;
			interrupts = <0x00 0x33 0x04>;
			clocks = <&clk_hosc>;
			phandle = <0x159>;
		};

		rtc: rtc@07000000 {
			compatible = "allwinner,sunxi-rtc";
			device_type = "rtc";
			wakeup-source;
			auto_switch;
			reg = <0x00 0x7000000 0x00 0x200>;
			interrupts = <0x00 0x6c 0x04>;
			gpr_offset = <0x100>;
			gpr_len = <0x08>;
			gpr_cur_pos = <0x06>;
			phandle = <0x15a>;
		};

		wdt: watchdog@030090a0 {
			compatible = "allwinner,sun50i-wdt";
			reg = <0x00 0x30090a0 0x00 0x20>;
			interrupts = <0x00 0x35 0x04>;
			phandle = <0x15b>;
		};



		uart0: uart@05000000 {
			compatible = "allwinner,sun50i-uart";
			device_type = "uart0";
			reg = <0x00 0x5000000 0x00 0x400>;
			interrupts = <0x00 0x00 0x04>;
			clocks = <&clk_uart0>;
			pinctrl-names = "default\0sleep";
			pinctrl-1 = <&uart0_pins_b>;
			uart0_port = <0x00>;
			uart0_type = <0x02>;
			status = "okay";
			uart-supply = <&reg_cldo3>;
			phandle = <0x15e>;
			pinctrl-0 = <&uart0_pins_a>;
		};

		uart1: uart@05000400 {
			compatible = "allwinner,sun50i-uart";
			device_type = "uart1";
			reg = <0x00 0x5000400 0x00 0x400>;
			interrupts = <0x00 0x01 0x04>;
			clocks = <&clk_uart1>;
			pinctrl-names = "default\0sleep";
			pinctrl-0 = <&uart1_pins_a>;
			pinctrl-1 = <&uart1_pins_b>;
			uart1_port = <0x01>;
			uart1_type = <0x04>;
			status = "okay";
			phandle = <0x15f>;
		};







		twi6: s_twi@0x07081400 {
			#address-cells = <0x01>;
			#size-cells = <0x00>;
			compatible = "allwinner,sun50i-twi";
			reg = <0x00 0x7081400 0x00 0x200>;
			interrupts = <0x00 0x71 0x04>;
			clocks = <&clk_stwi0>;
			clock-frequency = <0x30d40>;
			pinctrl-names = "default\0sleep";
			pinctrl-0 = <&s_twi0_pins_a>;
			pinctrl-1 = <&s_twi0_pins_b>;
			status = "okay";
			twi_drv_used = <0x00>;
			no_suspend = <0x01>;
			phandle = <0x166>;

			tcs0: tcs@41 {
				compatible = "ti,tcs4838";
				reg = <0x41>;
				status = "okay";
				tcs4838_delay = <0x00>;
				phandle = <0x167>;

				regulator1: regulators@1 {
					phandle = <0x168>;

					reg_tcs0: dcdc0 {
						regulator-name = "tcs4838-dcdc0";
						regulator-min-microvolt = <0xadf34>;
						regulator-max-microvolt = <0x16e360>;
						regulator-always-on;
						regulator-boot-on;
						phandle = <0x102>;
					};

					reg_tcs1: dcdc1 {
						regulator-name = "tcs4838-dcdc1";
						regulator-min-microvolt = <0xadf34>;
						regulator-max-microvolt = <0x16e360>;
						phandle = <0x169>;
					};
				};
			};

			pmu0: pmu@34 {
				compatible = "x-powers,axp2202";
				reg = <0x34>;
				status = "okay";
				interrupts = <0x00 0x08>;
				interrupt-parent = <&nmi_intc>;
				x-powers,drive-vbus-en;
				pmu_reset = <0x01>;
				pmu_irq_wakeup = <0x01>;
				pmu_hot_shutdown = <0x01>;
				wakeup-source;
				phandle = <0x16a>;

				usb_power_supply: usb_power_supply {
					compatible = "x-powers,axp2202-usb-power-supply";
					status = "okay";
					pmu_usbpc_vol = <0x11f8>;
					pmu_usbpc_cur = <0x1f4>;
					pmu_usbad_vol = <0xfa0>;
					pmu_usbad_cur = <0x9c4>;
					pmu_usb_typec_used = <0x01>;
					det_acin_supply = <&gpio_power_supply>;
					pmu_acin_usbid_drv = <0x45 0x07 0x0c 0x00 0xffffffff 0xffffffff 0xffffffff>;
					pmu_vbus_det_gpio = <0x45 0x07 0x0d 0x00 0xffffffff 0xffffffff 0xffffffff>;
					phandle = <0x46>;
				};

				gpio_power_supply: gpio_power_supply {
					compatible = "x-powers,gpio-supply";
					status = "disabled";
					pmu_acin_det_gpio = <0x45 0x07 0x0e 0x00 0xffffffff 0xffffffff 0xffffffff>;
					det_usb_supply = <&usb_power_supply>;
					phandle = <0x44>;
				};

				bat_power_supply: bat-power-supply {
					compatible = "x-powers,axp2202-bat-power-supply";
					param = <0x47>;
					status = "okay";
					pmu_chg_ic_temp = <0x00>;
					pmu_pre_chg = <0x1c2>;
					pmu_battery_rdc = <0x93>;
					pmu_battery_cap = <0xbb8>;
					pmu_runtime_chgcur = <0x3e8>;
					pmu_suspend_chgcur = <0x79e>;
					pmu_shutdown_chgcur = <0x79e>;
					pmu_init_chgvol = <0x1068>;
					pmu_battery_warning_level1 = <0x05>;
					pmu_battery_warning_level2 = <0x00>;
					pmu_chgled_func = <0x00>;
					pmu_chgled_type = <0x00>;
					pmu_bat_para1 = <0x00>;
					pmu_bat_para2 = <0x00>;
					pmu_bat_para3 = <0x01>;
					pmu_bat_para4 = <0x0c>;
					pmu_bat_para5 = <0x18>;
					pmu_bat_para6 = <0x21>;
					pmu_bat_para7 = <0x27>;
					pmu_bat_para8 = <0x2b>;
					pmu_bat_para9 = <0x2e>;
					pmu_bat_para10 = <0x30>;
					pmu_bat_para11 = <0x32>;
					pmu_bat_para12 = <0x34>;
					pmu_bat_para13 = <0x37>;
					pmu_bat_para14 = <0x3b>;
					pmu_bat_para15 = <0x3f>;
					pmu_bat_para16 = <0x44>;
					pmu_bat_para17 = <0x46>;
					pmu_bat_para18 = <0x48>;
					pmu_bat_para19 = <0x4b>;
					pmu_bat_para20 = <0x4d>;
					pmu_bat_para21 = <0x4f>;
					pmu_bat_para22 = <0x51>;
					pmu_bat_para23 = <0x55>;
					pmu_bat_para24 = <0x57>;
					pmu_bat_para25 = <0x5e>;
					pmu_bat_para26 = <0x60>;
					pmu_bat_para27 = <0x62>;
					pmu_bat_para28 = <0x63>;
					pmu_bat_para29 = <0x64>;
					pmu_bat_para30 = <0x64>;
					pmu_bat_para31 = <0x64>;
					pmu_bat_para32 = <0x64>;
					pmu_bat_temp_enable = <0x01>;
					pmu_jetia_en = <0x01>;
					pmu_bat_charge_ltf = <0x56e>;
					pmu_bat_charge_htf = <0xce>;
					pmu_bat_shutdown_ltf = <0x88e>;
					pmu_bat_shutdown_htf = <0x96>;
					pmu_jetia_cool = <0x2d2>;
					pmu_jetia_warm = <0xc4>;
					pmu_jcool_ifall = <0x01>;
					pmu_jwarm_ifall = <0x01>;
					pmu_bat_temp_para1 = <0x11ef>;
					pmu_bat_temp_para2 = <0xadd>;
					pmu_bat_temp_para3 = <0x88e>;
					pmu_bat_temp_para4 = <0x6ca>;
					pmu_bat_temp_para5 = <0x56e>;
					pmu_bat_temp_para6 = <0x45e>;
					pmu_bat_temp_para7 = <0x38a>;
					pmu_bat_temp_para8 = <0x25e>;
					pmu_bat_temp_para9 = <0x19f>;
					pmu_bat_temp_para10 = <0x122>;
					pmu_bat_temp_para11 = <0xf4>;
					pmu_bat_temp_para12 = <0xce>;
					pmu_bat_temp_para13 = <0xaf>;
					pmu_bat_temp_para14 = <0x96>;
					pmu_bat_temp_para15 = <0x6e>;
					pmu_bat_temp_para16 = <0x53>;
					wakeup_bat_out;
					wakeup_low_warning1;
					wakeup_low_warning2;
					phandle = <0x16b>;
				};

				powerkey0: powerkey@0 {
					status = "okay";
					compatible = "x-powers,axp2101-pek";
					pmu_powkey_off_time = <0x2710>;
					pmu_powkey_off_func = <0x00>;
					pmu_powkey_off_en = <0x01>;
					pmu_powkey_long_time = <0x5dc>;
					pmu_powkey_on_time = <0x200>;
					wakeup_rising;
					wakeup_falling;
					phandle = <0x16c>;
				};

				regulator0: regulators@0 {
					phandle = <0x16d>;

					reg_dcdc1: dcdc1 {
						regulator-name = "axp2202-dcdc1";
						regulator-min-microvolt = <0x7a120>;
						regulator-max-microvolt = <0x177fa0>;
						regulator-ramp-delay = <0xfa>;
						regulator-enable-ramp-delay = <0x3e8>;
						regulator-boot-on;
						regulator-always-on;
						phandle = <0x49>;
					};

					reg_dcdc2: dcdc2 {
						regulator-name = "axp2202-dcdc2";
						regulator-min-microvolt = <0x7a120>;
						regulator-max-microvolt = <0x33e140>;
						regulator-ramp-delay = <0xfa>;
						regulator-enable-ramp-delay = <0x3e8>;
						regulator-boot-on;
						regulator-always-on;
						phandle = <0x4a>;
					};

					reg_dcdc3: dcdc3 {
						regulator-name = "axp2202-dcdc3";
						regulator-min-microvolt = <0x7a120>;
						regulator-max-microvolt = <0x1c1380>;
						regulator-ramp-delay = <0xfa>;
						regulator-enable-ramp-delay = <0x3e8>;
						regulator-always-on;
						phandle = <0x4b>;
					};

					reg_dcdc4: dcdc4 {
						regulator-name = "axp2202-dcdc4";
						regulator-min-microvolt = <0xf4240>;
						regulator-max-microvolt = <0x387520>;
						regulator-ramp-delay = <0xfa>;
						regulator-enable-ramp-delay = <0x3e8>;
						phandle = <0x4c>;
					};

					reg_rtcldo: rtcldo {
						regulator-name = "axp2202-rtcldo";
						regulator-min-microvolt = <0x1b7740>;
						regulator-max-microvolt = <0x1b7740>;
						regulator-boot-on;
						regulator-always-on;
						phandle = <0x4d>;
					};

					reg_aldo1: aldo1 {
						regulator-name = "axp2202-aldo1";
						regulator-min-microvolt = <0x7a120>;
						regulator-max-microvolt = <0x3567e0>;
						regulator-enable-ramp-delay = <0x3e8>;
						phandle = <0x4e>;
					};

					reg_aldo2: aldo2 {
						regulator-name = "axp2202-aldo2";
						regulator-min-microvolt = <0x7a120>;
						regulator-max-microvolt = <0x3567e0>;
						regulator-enable-ramp-delay = <0x3e8>;
						regulator-boot-on;
						regulator-always-on;
						phandle = <0x4f>;
					};

					reg_aldo3: aldo3 {
						regulator-name = "axp2202-aldo3";
						regulator-min-microvolt = <0x7a120>;
						regulator-max-microvolt = <0x3567e0>;
						regulator-enable-ramp-delay = <0x3e8>;
						regulator-always-on;
						regulator-boot-on;
						phandle = <0x50>;
					};

					reg_aldo4: aldo4 {
						regulator-name = "axp2202-aldo4";
						regulator-min-microvolt = <0x7a120>;
						regulator-max-microvolt = <0x3567e0>;
						regulator-enable-ramp-delay = <0x3e8>;
						regulator-always-on;
						regulator-boot-on;
						phandle = <0x51>;
					};

					reg_bldo1: bldo1 {
						regulator-name = "axp2202-bldo1";
						regulator-min-microvolt = <0x7a120>;
						regulator-max-microvolt = <0x3567e0>;
						regulator-enable-ramp-delay = <0x3e8>;
						phandle = <0x52>;
					};

					reg_bldo2: bldo2 {
						regulator-name = "axp2202-bldo2";
						regulator-min-microvolt = <0x7a120>;
						regulator-max-microvolt = <0x3567e0>;
						regulator-enable-ramp-delay = <0x3e8>;
						regulator-boot-on;
						regulator-always-on;
						phandle = <0x53>;
					};

					reg_bldo3: bldo3 {
						regulator-name = "axp2202-bldo3";
						regulator-min-microvolt = <0x7a120>;
						regulator-max-microvolt = <0x3567e0>;
						regulator-enable-ramp-delay = <0x3e8>;
						regulator-boot-on;
						regulator-always-on;
						regulator-off-in-suspend;
						phandle = <0x54>;
					};

					reg_bldo4: bldo4 {
						regulator-name = "axp2202-bldo4";
						regulator-min-microvolt = <0x7a120>;
						regulator-max-microvolt = <0x3567e0>;
						regulator-enable-ramp-delay = <0x3e8>;
						phandle = <0x55>;
					};

					reg_cldo1: cldo1 {
						regulator-name = "axp2202-cldo1";
						regulator-min-microvolt = <0x7a120>;
						regulator-max-microvolt = <0x3567e0>;
						regulator-enable-ramp-delay = <0x3e8>;
						phandle = <0x56>;
					};

					reg_cldo2: cldo2 {
						regulator-name = "axp2202-cldo2";
						regulator-min-microvolt = <0x7a120>;
						regulator-max-microvolt = <0x3567e0>;
						regulator-enable-ramp-delay = <0x3e8>;
						phandle = <0x57>;
					};

					reg_cldo3: cldo3 {
						regulator-name = "axp2202-cldo3";
						regulator-min-microvolt = <0x7a120>;
						regulator-max-microvolt = <0x3567e0>;
						regulator-ramp-delay = <0x9c4>;
						regulator-enable-ramp-delay = <0x3e8>;
						regulator-boot-on;
						phandle = <0x2a>;
					};

					reg_cldo4: cldo4 {
						regulator-name = "axp2202-cldo4";
						regulator-min-microvolt = <0x7a120>;
						regulator-max-microvolt = <0x3567e0>;
						regulator-enable-ramp-delay = <0x3e8>;
						phandle = <0x58>;
					};

					reg_cpusldo: cpusldo {
						regulator-name = "axp2202-cpusldo";
						regulator-min-microvolt = <0x7a120>;
						regulator-max-microvolt = <0x155cc0>;
						regulator-boot-on;
						regulator-always-on;
						phandle = <0x59>;
					};

					reg_vmid: vmid {
						regulator-name = "axp2202-vmid";
						regulator-enable-ramp-delay = <0x3e8>;
						phandle = <0x48>;
					};

					reg_drivevbus: drivevbus {
						regulator-name = "axp2202-drivevbus";
						regulator-enable-ramp-delay = <0x3e8>;
						drivevbusin-supply = <&reg_vmid>;
						phandle = <0x5a>;
					};
				};

				virtual-dcdc1 {
					compatible = "xpower-vregulator,dcdc1";
					dcdc1-supply = <&reg_dcdc1>;
				};

				virtual-dcdc2 {
					compatible = "xpower-vregulator,dcdc2";
					dcdc2-supply = <&reg_dcdc2>;
				};

				virtual-dcdc3 {
					compatible = "xpower-vregulator,dcdc3";
					dcdc3-supply = <&reg_dcdc3>;
				};

				virtual-dcdc4 {
					compatible = "xpower-vregulator,dcdc4";
					dcdc4-supply = <&reg_dcdc4>;
				};

				virtual-rtcldo {
					compatible = "xpower-vregulator,rtcldo";
					rtcldo-supply = <&reg_rtcldo>;
				};

				virtual-aldo1 {
					compatible = "xpower-vregulator,aldo1";
					aldo1-supply = <&reg_aldo1>;
				};

				virtual-aldo2 {
					compatible = "xpower-vregulator,aldo2";
					aldo2-supply = <&reg_aldo2>;
				};

				virtual-aldo3 {
					compatible = "xpower-vregulator,aldo3";
					aldo3-supply = <&reg_aldo3>;
				};

				virtual-aldo4 {
					compatible = "xpower-vregulator,aldo4";
					aldo4-supply = <&reg_aldo4>;
				};

				virtual-bldo1 {
					compatible = "xpower-vregulator,bldo1";
					bldo1-supply = <&reg_bldo1>;
				};

				virtual-bldo2 {
					compatible = "xpower-vregulator,bldo2";
					bldo2-supply = <&reg_bldo2>;
				};

				virtual-bldo3 {
					compatible = "xpower-vregulator,bldo3";
					bldo3-supply = <&reg_bldo3>;
				};

				virtual-bldo4 {
					compatible = "xpower-vregulator,bldo4";
					bldo4-supply = <&reg_bldo4>;
				};

				virtual-cldo1 {
					compatible = "xpower-vregulator,cldo1";
					cldo1-supply = <&reg_cldo1>;
				};

				virtual-cldo2 {
					compatible = "xpower-vregulator,cldo2";
					cldo2-supply = <&reg_cldo2>;
				};

				virtual-cldo3 {
					compatible = "xpower-vregulator,cldo3";
					cldo3-supply = <&reg_cldo3>;
				};

				virtual-cldo4 {
					compatible = "xpower-vregulator,cldo4";
					cldo4-supply = <&reg_cldo4>;
				};

				virtual-cpusldo {
					compatible = "xpower-vregulator,cpusldo";
					cpusldo-supply = <&reg_cpusldo>;
				};

				virtual-drivevbus {
					compatible = "xpower-vregulator,drivevbus";
					drivevbus-supply = <&reg_drivevbus>;
				};

				axp_gpio0: axp_gpio@0 {
					gpio-controller;
					#size-cells = <0x00>;
					#gpio-cells = <0x06>;
					status = "okay";
					phandle = <0x16e>;
				};
			};
		};

		twi0: twi@0x05002000 {
			#address-cells = <0x01>;
			#size-cells = <0x00>;
			compatible = "allwinner,sun50i-twi";
			device_type = "twi0";
			reg = <0x00 0x5002000 0x00 0x400>;
			interrupts = <0x00 0x07 0x04>;
			clocks = <&clk_twi0>;
			clock-frequency = <0x61a80>;
			pinctrl-names = "default\0sleep";
			pinctrl-0 = <&twi0_pins_a>;
			pinctrl-1 = <&twi0_pins_b>;
			status = "okay";
			phandle = <0x16f>;

		};


		twi2: twi@0x05002800 {
			#address-cells = <0x01>;
			#size-cells = <0x00>;
			compatible = "allwinner,sun50i-twi";
			device_type = "twi2";
			reg = <0x00 0x5002800 0x00 0x400>;
			interrupts = <0x00 0x09 0x04>;
			clocks = <&clk_twi2>;
			clock-frequency = <0x30d40>;
			pinctrl-names = "default\0sleep";
			pinctrl-0 = <&twi2_pins_a>;
			pinctrl-1 = <&twi2_pins_b>;
			status = "okay";
			twi-supply = <&reg_aldo2>;
			twi_vol = <0x3567e0>;
			phandle = <0x171>;
		};





		usbc0: usbc0@0 {
			device_type = "usbc0";
			compatible = "allwinner,sunxi-otg-manager";
			usb_port_type = <0x02>;
			usb_detect_type = <0x01>;
			usb_id_gpio = <0x45 0x07 0x08 0x00 0x00 0xffffffff 0xffffffff>;
			usb_det_vbus_gpio = "axp_ctrl";
			usb_regulator_io = "nocare";
			usb_wakeup_suspend = <0x00>;
			usb_luns = <0x03>;
			usb_serial_unique = <0x00>;
			usb_serial_number = "20080411";
			rndis_wceis = <0x01>;
			status = "okay";
			det_vbus_supply = <&usb_power_supply>;
			usbc-supply = <&reg_cldo3>;
			phandle = <0x176>;
		};

		udc: udc-controller@0x05100000 {
			compatible = "allwinner,sunxi-udc";
			reg = <0x00 0x5100000 0x00 0x1000 0x00 0x00 0x00 0x100 0x00 0x5200000 0x00 0x1000>;
			interrupts = <0x00 0x20 0x04>;
			clocks = <&clk_usbphy0 &clk_usbotg &clk_usbehci1 &clk_usbphy1>;
			status = "okay";
			det_vbus_supply = <&usb_power_supply>;
			udc-supply = <&reg_cldo3>;
			phandle = <0x177>;
		};



		usbc1: usbc1@0 {
			device_type = "usbc1";
			usb_regulator_io = "nocare";
			usb_wakeup_suspend = <0x00>;
			status = "okay";
			phandle = <0x17a>;
		};



		codec: codec@0x05096000 {
			compatible = "allwinner,sunxi-internal-codec";
			reg = <0x00 0x5096000 0x00 0x32c>;
			clocks = <&clk_pll_audiox4 &clk_codec_dac_1x &clk_codec_adc_1x &clk_pll_com &clk_pll_comdiv5>;
			device_type = "codec";
			status = "okay";
			mic1gain = <0x1f>;
			mic2gain = <0x1f>;
			adcdrc_cfg = <0x02>;
			adchpf_cfg = <0x01>;
			dacdrc_cfg = <0x02>;
			dachpf_cfg = <0x00>;
			digital_vol = <0x00>;
			lineout_vol = <0x1a>;
			headphonegain = <0x00>;
			pa_level = <0x01>;
			pa_msleep_time = <0x28>;
			gpio-spk = <0x45 0x07 0x06 0x01 0x01 0x01 0x01>;
			avcc-supply = <&reg_aldo4>;
			cpvin-supply = <&reg_cldo1>;
			phandle = <0x7f>;
		};

		cpudai: cpudai-controller@0x050906000 {
			compatible = "allwinner,sunxi-internal-cpudai";
			reg = <0x00 0x5096000 0x00 0x32c>;
			status = "okay";
			phandle = <0x7e>;
		};

		sndcodec: sound@0 {
			compatible = "allwinner,sunxi-codec-machine";
			interrupts = <0x00 0x19 0x04>;
			sunxi,cpudai-controller = <0x7e>;
			sunxi,audio-codec = <0x7f>;
			/* 1, the codec's high detect mode, where TrimUI's tree says 0: at 0
			 * every plug reads backwards (headphones in at boot with the jack
			 * empty, out when plugged in); at 1 each one reads right, measured
			 * 2026-10-16 by setting the mode by hand and plugging in twice */
			hp_detect_case = <0x01>;
			device_type = "sndcodec";
			status = "okay";
			noheadphonemic = <0x01>;
			phandle = <0x17d>;
		};
















		ledc: ledc@0x05018000 {
			#address-cells = <0x01>;
			#size-cells = <0x00>;
			compatible = "allwinner,sunxi-leds";
			reg = <0x00 0x5018000 0x00 0x100>;
			interrupts = <0x00 0x23 0x04>;
			interrupt-names = "ledcirq";
			clocks = <&clk_ledc &clk_cpuapb>;
			clock-names = "clk_ledc\0clk_cpuapb";
			pinctrl-names = "default\0sleep";
			pinctrl-0 = <&ledc_pins_a>;
			pinctrl-1 = <&ledc_pins_b>;
			led_count = <0x17>;
			output_mode = "RGB";
			reset_ns = <0x54>;
			t1h_ns = <0x320>;
			t1l_ns = <0x1c2>;
			t0h_ns = <0x190>;
			t0l_ns = <0x352>;
			wait_time0_ns = <0x54>;
			wait_time1_ns = <0x54>;
			wait_data_time_ns = <0x927c0>;
			status = "okay";
			phandle = <0x187>;
		};



		sdc0: sdmmc@04020000 {
			compatible = "allwinner,sunxi-mmc-v5p3x";
			device_type = "sdc0";
			reg = <0x00 0x4020000 0x00 0x1000>;
			interrupts = <0x00 0x27 0x04>;
			clocks = <&clk_hosc &clk_pll_periph1x2 &clk_sdmmc0_mod &clk_sdmmc0_bus &clk_sdmmc0_rst>;
			clock-names = "osc24m\0pll_periph\0mmc\0ahb\0rst";
			pinctrl-names = "default\0sleep\0uart_jtag";
			pinctrl-0 = <&sdc0_pins_a>;
			pinctrl-1 = <&sdc0_pins_b>;
			pinctrl-2 = <&sdc0_pins_c>;
			max-frequency = <0x8f0d180>;
			bus-width = <0x04>;
			cap-sd-highspeed;
			cap-wait-while-busy;
			no-sdio;
			no-mmc;
			status = "okay";
			cd-gpios = <&pio 0x05 0x06 0x06 0x01 0x03 0xffffffff>;
			cd-used-24M;
			sd-uhs-sdr50;
			sd-uhs-ddr50;
			sd-uhs-sdr104;
			sunxi-power-save-mode;
			ctl-spec-caps = <0x08>;
			vmmc-supply = <&reg_cldo3>;
			vqmmc33sw-supply = <&reg_cldo3>;
			vdmmc33sw-supply = <&reg_cldo3>;
			vqmmc18sw-supply = <&reg_cldo1>;
			vdmmc18sw-supply = <&reg_cldo1>;
			phandle = <0x18a>;
		};

		sdc1: sdmmc@04021000 {
			compatible = "allwinner,sunxi-mmc-v5p3x";
			device_type = "sdc1";
			reg = <0x00 0x4021000 0x00 0x1000>;
			interrupts = <0x00 0x28 0x04>;
			clocks = <&clk_hosc &clk_pll_periph1x2 &clk_sdmmc1_mod &clk_sdmmc1_bus &clk_sdmmc1_rst>;
			clock-names = "osc24m\0pll_periph\0mmc\0ahb\0rst";
			pinctrl-names = "default\0sleep";
			pinctrl-0 = <&sdc1_pins_a>;
			pinctrl-1 = <&sdc1_pins_b>;
			max-frequency = <0x8f0d180>;
			bus-width = <0x04>;
			cap-sd-highspeed;
			no-mmc;
			keep-power-in-suspend;
			sunxi-dly-52M-ddr4 = <0x01 0x00 0x00 0x00 0x02>;
			sunxi-dly-104M = <0x01 0x00 0x00 0x00 0x01>;
			sunxi-dly-208M = <0x01 0x00 0x00 0x00 0x01>;
			status = "okay";
			no-sd;
			sd-uhs-sdr50;
			sd-uhs-ddr50;
			sd-uhs-sdr104;
			sdio-used-1v8;
			cap-sdio-irq;
			ignore-pm-notify;
			ctl-spec-caps = <0x08>;
			phandle = <0x18b>;
		};



		disp: disp@06000000 {
			compatible = "allwinner,sunxi-disp";
			reg = <0x00 0x6000000 0x00 0x3fffff 0x00 0x6800000 0x00 0x3fffff 0x00 0x6510000 0x00 0xfff 0x00 0x6d10000 0x00 0xfff 0x00 0x6511000 0x00 0xfff 0x00 0x6d11000 0x00 0xfff 0x00 0x6504000 0x00 0x1fff>;
			interrupts = <0x00 0x45 0x04 0x00 0x46 0x04 0x00 0x44 0x04>;
			clocks = <&clk_de0 &clk_de1 &clk_display_top &clk_dpss_top0 &clk_dpss_top1 &clk_tcon_lcd0 &clk_tcon_lcd1 &clk_lvds &clk_lvds1 &clk_mipi_host>;
			fb_base = <0x00>;
			iommus = <&mmu_aw 0x00 0x00>;
			status = "okay";
			disp_init_enable = <0x01>;
			disp_mode = <0x00>;
			screen0_output_type = <0x01>;
			screen0_output_mode = <0x04>;
			screen1_output_type = <0x01>;
			screen1_output_mode = <0x04>;
			screen1_output_format = <0x00>;
			screen1_output_bits = <0x00>;
			screen1_output_eotf = <0x04>;
			screen1_output_cs = <0x101>;
			screen1_output_dvi_hdmi = <0x02>;
			screen1_output_range = <0x02>;
			screen1_output_scan = <0x00>;
			screen1_output_aspect_ratio = <0x08>;
			dev0_output_type = <0x01>;
			dev0_output_mode = <0x04>;
			dev0_screen_id = <0x00>;
			dev0_do_hpd = <0x00>;
			dev1_output_type = <0x04>;
			dev1_output_mode = <0x0a>;
			dev1_screen_id = <0x01>;
			dev1_do_hpd = <0x01>;
			def_output_dev = <0x00>;
			hdmi_mode_check = <0x01>;
			fb0_format = <0x00>;
			fb0_width = <0x400>;
			fb0_height = <0x300>;
			fb1_format = <0x00>;
			fb1_width = <0x00>;
			fb1_height = <0x00>;
			chn_cfg_mode = <0x01>;
			disp_para_zone = <0x01>;
			cldo4-supply = <&reg_cldo4>;
			cldo1-supply = <&reg_cldo1>;
			phandle = <0x18e>;
		};




		lcd0: lcd0@01c0c000 {
			compatible = "allwinner,sunxi-lcd0";
			pinctrl-names = "active\0sleep";
			status = "okay";
			lcd_used = <0x01>;
			lcd_driver_name = "otm1289a";
			lcd_if = <0x04>;
			lcd_x = <0x400>;
			lcd_y = <0x300>;
			lcd_width = <0x87>;
			lcd_height = <0xd8>;
			lcd_dclk_freq = <0x33>;
			lcd_hbp = <0x14>;
			lcd_ht = <0x438>;
			lcd_hspw = <0x04>;
			lcd_vbp = <0x09>;
			lcd_vt = <0x310>;
			lcd_vspw = <0x04>;
			lcd_backlight = <0x04>;
			lcd_pwm_used = <0x01>;
			lcd_pwm_ch = <0x00>;
			lcd_pwm_freq = <0xc350>;
			lcd_pwm_pol = <0x00>;
			lcd_pwm_max_limit = <0xc8>;
			lcd_dsi_if = <0x00>;
			lcd_dsi_lane = <0x04>;
			lcd_dsi_format = <0x00>;
			lcd_dsi_te = <0x00>;
			lcd_dsi_eotp = <0x00>;
			lcd_frm = <0x00>;
			lcd_gamma_en = <0x00>;
			lcd_bright_curve_en = <0x00>;
			lcd_cmap_en = <0x00>;
			deu_mode = <0x00>;
			lcdgamma4iep = <0x16>;
			smart_color = <0x5a>;
			lcd_pin_power = "cldo1";
			lcd_power0 = "cldo1";
			lcd_power1 = "cldo4";
			lcd_gpio_0 = <0x45 0x03 0x16 0x01 0x00 0x03 0x01>;
			pinctrl-0 = <&dsi4lane_pins_a>;
			pinctrl-1 = <&dsi4lane_pins_b>;
			lcd_bl_en = <0x45 0x07 0x12 0x01 0x01 0x00 0x03 0x01>;
			phandle = <0x192>;
		};



		pwm: pwm@0300a000 {
			compatible = "allwinner,sunxi-pwm";
			reg = <0x00 0x300a000 0x00 0x3ff>;
			clocks = <&clk_pwm>;
			pwm-number = <0x10>;
			pwm-base = <0x00>;
			pwms = <&pwm0 &pwm1 &pwm2 &pwm3 &pwm4 &pwm5 &pwm6 &pwm7 &pwm8 &pwm9 &pwm10 &pwm11 &pwm12 &pwm13 &pwm14 &pwm15>;
			phandle = <0x195>;
		};

		s_pwm: pwm@07020c00 {
			compatible = "allwinner,sunxi-pwm";
			reg = <0x00 0x7020c00 0x00 0x3ff>;
			clocks = <&clk_spwm>;
			pwm-number = <0x01>;
			pwm-base = <0x10>;
			pwms = <&s_pwm0>;
			phandle = <0x196>;
		};

		pwm0: pwm0@0300a000 {
			compatible = "allwinner,sunxi-pwm0";
			pinctrl-names = "active\0sleep";
			reg_base = <0x300a000>;
			pinctrl-0 = <&pwm0_pin_a>;
			pinctrl-1 = <&pwm0_pin_b>;
			phandle = <0xc5>;
		};

		pwm1: pwm1@0300a000 {
			compatible = "allwinner,sunxi-pwm1";
			pinctrl-names = "active\0sleep";
			reg_base = <0x300a000>;
			phandle = <0xc6>;
		};

		pwm2: pwm2@0300a000 {
			compatible = "allwinner,sunxi-pwm2";
			pinctrl-names = "active\0sleep";
			reg_base = <0x300a000>;
			phandle = <0xc7>;
		};

		pwm3: pwm3@0300a000 {
			compatible = "allwinner,sunxi-pwm3";
			pinctrl-names = "active\0sleep";
			reg_base = <0x300a000>;
			phandle = <0xc8>;
		};

		pwm4: pwm4@0300a000 {
			compatible = "allwinner,sunxi-pwm4";
			pinctrl-names = "active\0sleep";
			reg_base = <0x300a000>;
			phandle = <0xc9>;
		};

		pwm5: pwm5@0300a000 {
			compatible = "allwinner,sunxi-pwm5";
			pinctrl-names = "active\0sleep";
			reg_base = <0x300a000>;
			phandle = <0xca>;
		};

		pwm6: pwm6@0300a000 {
			compatible = "allwinner,sunxi-pwm6";
			pinctrl-names = "active\0sleep";
			reg_base = <0x300a000>;
			phandle = <0xcb>;
		};

		pwm7: pwm7@0300a000 {
			compatible = "allwinner,sunxi-pwm7";
			pinctrl-names = "active\0sleep";
			reg_base = <0x300a000>;
			phandle = <0xcc>;
		};

		pwm8: pwm8@0300a000 {
			compatible = "allwinner,sunxi-pwm8";
			pinctrl-names = "active\0sleep";
			reg_base = <0x300a000>;
			phandle = <0xcd>;
		};

		pwm9: pwm9@0300a000 {
			compatible = "allwinner,sunxi-pwm9";
			pinctrl-names = "active\0sleep";
			reg_base = <0x300a000>;
			phandle = <0xce>;
		};

		pwm10: pwm10@0300a000 {
			compatible = "allwinner,sunxi-pwm10";
			pinctrl-names = "active\0sleep";
			reg_base = <0x300a000>;
			phandle = <0xcf>;
		};

		pwm11: pwm11@0300a000 {
			compatible = "allwinner,sunxi-pwm11";
			pinctrl-names = "active\0sleep";
			reg_base = <0x300a000>;
			phandle = <0xd0>;
		};

		pwm12: pwm12@0300a000 {
			compatible = "allwinner,sunxi-pwm12";
			pinctrl-names = "active\0sleep";
			reg_base = <0x300a000>;
			phandle = <0xd1>;
		};

		pwm13: pwm13@0300a000 {
			compatible = "allwinner,sunxi-pwm13";
			pinctrl-names = "active\0sleep";
			reg_base = <0x300a000>;
			phandle = <0xd2>;
		};

		pwm14: pwm14@0300a000 {
			compatible = "allwinner,sunxi-pwm14";
			pinctrl-names = "active\0sleep";
			reg_base = <0x300a000>;
			phandle = <0xd3>;
		};

		pwm15: pwm15@0300a000 {
			compatible = "allwinner,sunxi-pwm15";
			pinctrl-names = "active\0sleep";
			reg_base = <0x300a000>;
			phandle = <0xd4>;
		};

		s_pwm0: s_pwm0@07020c00 {
			compatible = "allwinner,sunxi-pwm16";
			pinctrl-names = "active\0sleep";
			reg_base = <0x7020c00>;
			phandle = <0xd6>;
		};








		ths: thermal_sensor {
			compatible = "allwinner,sun50iw10p1-ths";
			reg = <0x00 0x5070400 0x00 0x400>;
			clocks = <&clk_ths>;
			clock-names = "bus";
			nvmem-cells = <&ths_calib>;
			nvmem-cell-names = "calibration";
			#thermal-sensor-cells = <0x01>;
			phandle = <0xf0>;
		};

		thermal-zones {

			cpu_thermal_zone {
				polling-delay-passive = <0x1f4>;
				polling-delay = <0x3e8>;
				thermal-sensors = <&ths 0x00>;
				sustainable-power = <0x4b0>;
				k_po = <0x42>;
				k_pu = <0x84>;
				k_i = <0x00>;

				cpu_trips: trips {
					phandle = <0x1af>;

					cpu_threshold: trip-point@0 {
						temperature = <0xe290>;
						type = "passive";
						hysteresis = <0x00>;
						phandle = <0x1b0>;
					};

					cpu_target: trip-point@1 {
						temperature = <0xf618>;
						type = "passive";
						hysteresis = <0x00>;
						phandle = <0xf1>;
					};

					cpu_crit: cpu_crit@0 {
						temperature = <0x15f90>;
						type = "critical";
						hysteresis = <0x00>;
						phandle = <0x1b1>;
					};
				};

				cooling-maps {

					map0 {
						trip = <0xf1>;
						cooling-device = <&cpu0 0xffffffff 0xffffffff>;
						contribution = <0x400>;
					};
				};
			};

			gpu_thermal_zone {
				polling-delay-passive = <0x1f4>;
				polling-delay = <0x3e8>;
				thermal-sensors = <&ths 0x01>;
				sustainable-power = <0x44c>;
			};

			ddr_thermal_zone {
				polling-delay-passive = <0x00>;
				polling-delay = <0x00>;
				thermal-sensors = <&ths 0x02>;
			};
		};


		keyboard0: keyboard {
			compatible = "allwinner,keyboard_1350mv";
			reg = <0x00 0x5070800 0x00 0x400>;
			interrupts = <0x00 0x16 0x00>;
			clocks = <&clk_lradc>;
			status = "okay";
			key_cnt = <0x03>;
			key0 = <0x1db 0x7372>;
			key1 = <0x286 0x73>;
			key2 = <0x384 0x72>;
			key3 = <0x2ee 0x1c>;
			key4 = <0x370 0x66>;
			phandle = <0x1b3>;
		};

		gmac0: eth@05020000 {
			compatible = "allwinner,sunxi-gmac";
			reg = <0x00 0x5020000 0x00 0x10000 0x00 0x3000030 0x00 0x04>;
			interrupts = <0x00 0x10 0x04>;
			interrupt-names = "gmacirq";
			clocks = <&clk_gmac0 &clk_gmac0_25m>;
			clock-names = "gmac\0ephy";
			device_type = "gmac0";
			pinctrl-0 = <&gmac_pins_a>;
			pinctrl-1 = <&gmac_pins_b>;
			pinctrl-names = "default\0sleep";
			phy-mode;
			tx-delay = <0x07>;
			rx-delay = <0x1f>;
			phy-rst;
			gmac-power0;
			gmac-power1;
			gmac-power2;
			status = "disable";
			phandle = <0x1b4>;
		};

		gmac1: eth@05030000 {
			compatible = "allwinner,sunxi-gmac";
			reg = <0x00 0x5030000 0x00 0x10000 0x00 0x3000034 0x00 0x04>;
			interrupts = <0x00 0x11 0x04>;
			interrupt-names = "gmacirq";
			clocks = <&clk_gmac1 &clk_gmac1_25m>;
			clock-names = "gmac\0ephy";
			device_type = "gmac1";
			pinctrl-0 = <&gmac1_pins_a>;
			pinctrl-1 = <&gmac1_pins_b>;
			pinctrl-names = "default\0sleep";
			phy-mode;
			tx-delay = <0x07>;
			rx-delay = <0x1f>;
			phy-rst;
			gmac-power0;
			gmac-power1;
			gmac-power2;
			status = "disable";
			phandle = <0x1b5>;
		};

		standby_param: standby_param {
			reg = <0x00 0x7000400 0x00 0x00>;
			vdd-cpu = <0x01>;
			vdd-sys = <0x02>;
			vcc-pll = <0x80>;
			osc24m-on = <0x01>;
			phandle = <0x1b6>;
		};

		hall_para {
			hall_name = "MH248";
			status = "okay";
			hall_int_port = <0x61 0x0b 0x09 0x06 0x01 0xffffffff 0xffffffff>;
		};

		wlan: wlan@0 {
			compatible = "allwinner,sunxi-wlan";
			clocks = <&clk_losc_out &clk_dcxo_out>;
			pinctrl-0;
			pinctrl-names;
			wlan_busnum = <0x01>;
			wlan_power_num = <0x01>;
			wlan_power1 = "axp2202-bldo1";
			wlan_io_regulator = "axp2202-aldo3";
			wlan_io_voltage = <0x325aa0>;
			wlan_regon = <0x61 0x0b 0x05 0x01 0xffffffff 0xffffffff 0x00>;
			wlan_hostwake = <0x61 0x0b 0x06 0x06 0xffffffff 0xffffffff 0x00>;
			chip_en;
			power_en;
			status = "okay";
			phandle = <0x1b7>;
		};

		bt: bt@0 {
			compatible = "allwinner,sunxi-bt";
			clocks = <&clk_losc_out &clk_dcxo_out>;
			bt_power_num = <0x01>;
			bt_power1 = "axp2202-bldo1";
			bt_io_regulator = "axp2202-aldo3";
			bt_io_voltage = <0x325aa0>;
			bt_rst_n = <0x61 0x0b 0x02 0x01 0xffffffff 0xffffffff 0x00>;
			status = "okay";
			phandle = <0x1b8>;
		};

		btlpm: btlpm@0 {
			compatible = "allwinner,sunxi-btlpm";
			uart_index = <0x01>;
			bt_wake = <0x61 0x0b 0x04 0x01 0xffffffff 0xffffffff 0x01>;
			bt_hostwake = <0x61 0x0b 0x03 0x06 0xffffffff 0xffffffff 0x01>;
			status = "okay";
			phandle = <0x1b9>;
		};

		addr_mgt: addr_mgt@0 {
			compatible = "allwinner,sunxi-addr_mgt";
			type_addr_wifi = <0x00>;
			type_addr_bt = <0x00>;
			type_addr_eth = <0x00>;
			status = "okay";
			phandle = <0x1ba>;
		};

		product {
			device_type = "product";
			version = "100";
			machine = "evb";
		};

		platform {
			device_type = "platform";
			eraseflag = <0x01>;
			next_work = <0x03>;
			debug_mode = <0x08>;
		};

		target {
			device_type = "target";
			boot_clock = <0x3f0>;
			storage_type = <0xffffffff>;
			burn_key = <0x01>;
			dragonboard_test = <0x00>;
			power_mode = <0x00>;
		};

		power_sply {
			device_type = "power_sply";
			dcdc1_vol = <0xf45ec>;
			aldo1_vol = <0x10cfe8>;
			aldo2_vol = <0x10d5c4>;
			aldo3_vol = <0xf4f24>;
			aldo4_vol = <0xf4948>;
			bldo1_vol = <0xce4>;
			bldo2_vol = <0xf4948>;
			bldo3_vol = <0xf4f24>;
			bldo4_vol = <0x10cfe8>;
			cldo1_vol = <0xf4948>;
			cldo3_vol = <0xf4f24>;
			cldo4_vol = <0x10d5c4>;
			cpusldo_vol = <0xf45c4>;
			dcdc1_mode = <0x01>;
			dcdc2_mode = <0x01>;
			battery_exist = <0x01>;
			ntc_status = <0x01>;
		};

		card_boot {
			device_type = "card_boot";
			logical_start = <0xa000>;
			sprite_gpio0 = <0x45 0x07 0x06 0x01 0xffffffff 0xffffffff 0x01>;
		};

		fastboot_key {
			device_type = "fastboot_key";
			key_max = <0x2b>;
			key_min = <0x27>;
		};

		recovery_key {
			device_type = "recovery_key";
			key_max = <0x0e>;
			key_min = <0x0b>;
		};

		pm_para {
			device_type = "pm_para";
			standby_mode = <0x01>;
		};

		card0_boot_para {
			device_type = "card0_boot_para";
			card_ctrl = <0x00>;
			card_high_speed = <0x01>;
			card_line = <0x04>;
			pinctrl-0 = <&{/soc@03000000/pinctrl@0300b000/card0_boot_para@0}>;
		};

		card2_boot_para {
			device_type = "card2_boot_para";
			card_ctrl = <0x02>;
			card_high_speed = <0x01>;
			card_line = <0x08>;
			pinctrl-0 = <&{/soc@03000000/pinctrl@0300b000/card2_boot_para@0} &{/soc@03000000/pinctrl@0300b000/card2_boot_para@1}>;
			sdc_tm4_hs200_max_freq = <0x96>;
			sdc_tm4_hs400_max_freq = <0x64>;
			sdc_ex_dly_used = <0x02>;
			sdc_io_1v8 = <0x01>;
			sdc_tm4_win_th = <0x08>;
		};

		gpio_bias {
			device_type = "gpio_bias";
			pc_bias = <0x708>;
			pl_bias = <0xce4>;
			pl_supply = "aldo3_vol";
		};

		power_delay {
			device_type = "power_delay";
			aldo3_vol_delay = <0x4e20>;
		};

		uart_para {
			device_type = "uart_para";
			uart_debug_port = <0x00>;
			pinctrl-0 = <&{/soc@03000000/pinctrl@0300b000/uart_para@0}>;
		};

		jtag_para {
			device_type = "jtag_para";
			jtag_enable = <0x01>;
			pinctrl-0 = <&{/soc@03000000/pinctrl@0300b000/jtag_para@0}>;
		};

		clock {
			device_type = "clock";
			pll4 = <0x12c>;
			pll6 = <0x258>;
			pll8 = <0x168>;
			pll9 = <0x129>;
			pll10 = <0x108>;
		};

		dram_select_para {
			device_type = "dram_select_para";
			select_mode = <0x00>;
			gpadc_channel = <0x01>;
			select_gpio0 = <0x45 0x07 0x11 0x00 0x01 0xffffffff 0xffffffff>;
			select_gpio1;
			select_gpio2;
			select_gpio3;
			index_ddr4_lijing = <0x0e>;
		};

		dram_para1 {
			device_type = "dram_para1";
			dram_clk = <0x240>;
			dram_type = <0x03>;
			dram_dx_odt = <0x7070707>;
			dram_dx_dri = <0xc0c0c0c>;
			dram_ca_dri = <0xe0e>;
			dram_para0 = <0x15101212>;
			dram_para1 = <0x30fa>;
			dram_para2 = <0x00>;
			dram_mr0 = <0x840>;
			dram_mr1 = <0x04>;
			dram_mr2 = <0x08>;
			dram_mr3 = <0x00>;
			dram_mr4 = <0x00>;
			dram_mr5 = <0x00>;
			dram_mr6 = <0x00>;
			dram_mr11 = <0x00>;
			dram_mr12 = <0x00>;
			dram_mr13 = <0x00>;
			dram_mr14 = <0x00>;
			dram_mr16 = <0x00>;
			dram_mr17 = <0x00>;
			dram_mr22 = <0x00>;
			dram_tpr0 = <0x00>;
			dram_tpr1 = <0x00>;
			dram_tpr2 = <0x00>;
			dram_tpr3 = <0x00>;
			dram_tpr6 = <0x33808080>;
			dram_tpr10 = <0x2f7458>;
			dram_tpr11 = <0xf0b0e0c>;
			dram_tpr12 = <0x19191818>;
			dram_tpr13 = <0x00>;
			dram_tpr14 = <0x26232323>;
		};

		dram_para2 {
			device_type = "dram_para2";
			dram_clk = <0x240>;
			dram_type = <0x07>;
			dram_dx_odt = <0x6060606>;
			dram_dx_dri = <0xc0c0c0c>;
			dram_ca_dri = <0x1919>;
			dram_para0 = <0x17171412>;
			dram_para1 = <0x30fa>;
			dram_para2 = <0x00>;
			dram_mr0 = <0x00>;
			dram_mr1 = <0xc3>;
			dram_mr2 = <0x06>;
			dram_mr3 = <0x02>;
			dram_mr4 = <0x00>;
			dram_mr5 = <0x00>;
			dram_mr6 = <0x00>;
			dram_mr11 = <0x00>;
			dram_mr12 = <0x00>;
			dram_mr13 = <0x00>;
			dram_mr14 = <0x00>;
			dram_mr16 = <0x00>;
			dram_mr17 = <0x1e1a1a17>;
			dram_mr22 = <0x2a28282b>;
			dram_tpr0 = <0x1616181e>;
			dram_tpr1 = <0x1c1a1a16>;
			dram_tpr2 = <0x18181818>;
			dram_tpr3 = <0x800000>;
			dram_tpr6 = <0x2fb88080>;
			dram_tpr10 = <0x2fbbcf>;
			dram_tpr11 = <0x1415110a>;
			dram_tpr12 = <0x14141616>;
			dram_tpr13 = <0x2008020>;
			dram_tpr14 = <0x25242629>;
		};

		dram_para3 {
			device_type = "dram_para3";
			dram_clk = <0x240>;
			dram_type = <0x07>;
			dram_dx_odt = <0x6060606>;
			dram_dx_dri = <0xc0c0c0c>;
			dram_ca_dri = <0x1919>;
			dram_para0 = <0x17171412>;
			dram_para1 = <0x30fa>;
			dram_para2 = <0x00>;
			dram_mr0 = <0x00>;
			dram_mr1 = <0xc3>;
			dram_mr2 = <0x06>;
			dram_mr3 = <0x02>;
			dram_mr4 = <0x00>;
			dram_mr5 = <0x00>;
			dram_mr6 = <0x00>;
			dram_mr11 = <0x00>;
			dram_mr12 = <0x00>;
			dram_mr13 = <0x00>;
			dram_mr14 = <0x00>;
			dram_mr16 = <0x00>;
			dram_mr17 = <0x1e1a1a17>;
			dram_mr22 = <0x2a28282b>;
			dram_tpr0 = <0x1616181e>;
			dram_tpr1 = <0x1c1a1a16>;
			dram_tpr2 = <0x18181818>;
			dram_tpr3 = <0x800000>;
			dram_tpr6 = <0x2fb88080>;
			dram_tpr10 = <0x2fbbcf>;
			dram_tpr11 = <0x1415110a>;
			dram_tpr12 = <0x14141616>;
			dram_tpr13 = <0x2008060>;
			dram_tpr14 = <0x25242629>;
		};

		dram_para4 {
			device_type = "dram_para4";
			dram_clk = <0x240>;
			dram_type = <0x07>;
			dram_dx_odt = <0x6060606>;
			dram_dx_dri = <0xc0c0c0c>;
			dram_ca_dri = <0x1919>;
			dram_para0 = <0x1b181215>;
			dram_para1 = <0x30fa>;
			dram_para2 = <0x00>;
			dram_mr0 = <0x00>;
			dram_mr1 = <0xc3>;
			dram_mr2 = <0x06>;
			dram_mr3 = <0x02>;
			dram_mr4 = <0x00>;
			dram_mr5 = <0x00>;
			dram_mr6 = <0x00>;
			dram_mr11 = <0x00>;
			dram_mr12 = <0x00>;
			dram_mr13 = <0x00>;
			dram_mr14 = <0x00>;
			dram_mr16 = <0x00>;
			dram_mr17 = <0x00>;
			dram_mr22 = <0x00>;
			dram_tpr0 = <0x16161a1e>;
			dram_tpr1 = <0x00>;
			dram_tpr2 = <0x00>;
			dram_tpr3 = <0x00>;
			dram_tpr6 = <0x2fb28080>;
			dram_tpr10 = <0x2fbbdf>;
			dram_tpr11 = <0x18150d11>;
			dram_tpr12 = <0x14141514>;
			dram_tpr13 = <0x81d2060>;
			dram_tpr14 = <0x1e1e2020>;
		};

		dram_para5 {
			device_type = "dram_para5";
			dram_clk = <0x2a0>;
			dram_type = <0x04>;
			dram_dx_odt = <0x3030303>;
			dram_dx_dri = <0xc0c0c0c>;
			dram_ca_dri = <0x1919>;
			dram_para0 = <0x252a2a24>;
			dram_para1 = <0xa0fa>;
			dram_para2 = <0x00>;
			dram_mr0 = <0x840>;
			dram_mr1 = <0x601>;
			dram_mr2 = <0x08>;
			dram_mr3 = <0x00>;
			dram_mr4 = <0x00>;
			dram_mr5 = <0x400>;
			dram_mr6 = <0x862>;
			dram_mr11 = <0x00>;
			dram_mr12 = <0x00>;
			dram_mr13 = <0x00>;
			dram_mr14 = <0x00>;
			dram_mr16 = <0x00>;
			dram_mr17 = <0x00>;
			dram_mr22 = <0x00>;
			dram_tpr0 = <0x211f38>;
			dram_tpr1 = <0x00>;
			dram_tpr2 = <0x00>;
			dram_tpr3 = <0x00>;
			dram_tpr6 = <0x3380a380>;
			dram_tpr10 = <0x802f7777>;
			dram_tpr11 = <0x21272820>;
			dram_tpr12 = <0x1f1f2525>;
			dram_tpr13 = <0x00>;
			dram_tpr14 = <0x29292c2c>;
		};

		dram_para6 {
			device_type = "dram_para6";
			dram_clk = <0x2a0>;
			dram_type = <0x04>;
			dram_dx_odt = <0x3030303>;
			dram_dx_dri = <0xc0c0c0c>;
			dram_ca_dri = <0x1919>;
			dram_para0 = <0x252a2a24>;
			dram_para1 = <0xa0fa>;
			dram_para2 = <0x00>;
			dram_mr0 = <0x840>;
			dram_mr1 = <0x601>;
			dram_mr2 = <0x08>;
			dram_mr3 = <0x00>;
			dram_mr4 = <0x00>;
			dram_mr5 = <0x400>;
			dram_mr6 = <0x862>;
			dram_mr11 = <0x00>;
			dram_mr12 = <0x00>;
			dram_mr13 = <0x00>;
			dram_mr14 = <0x00>;
			dram_mr16 = <0x00>;
			dram_mr17 = <0x00>;
			dram_mr22 = <0x00>;
			dram_tpr0 = <0x191638>;
			dram_tpr1 = <0x00>;
			dram_tpr2 = <0x00>;
			dram_tpr3 = <0x00>;
			dram_tpr6 = <0x3380a380>;
			dram_tpr10 = <0x802f7777>;
			dram_tpr11 = <0x21262820>;
			dram_tpr12 = <0x1f1f2525>;
			dram_tpr13 = <0x40>;
			dram_tpr14 = <0x29292c2c>;
		};

		dram_para7 {
			device_type = "dram_para7";
			dram_clk = <0x318>;
			dram_type = <0x08>;
			dram_dx_odt = <0x7070707>;
			dram_dx_dri = <0xd0d0d0d>;
			dram_ca_dri = <0xe0e>;
			dram_para0 = <0xd0a050c>;
			dram_para1 = <0x30ea>;
			dram_para2 = <0x1000>;
			dram_mr0 = <0x00>;
			dram_mr1 = <0x34>;
			dram_mr2 = <0x1b>;
			dram_mr3 = <0x33>;
			dram_mr4 = <0x03>;
			dram_mr5 = <0x00>;
			dram_mr6 = <0x00>;
			dram_mr11 = <0x04>;
			dram_mr12 = <0x72>;
			dram_mr13 = <0x00>;
			dram_mr14 = <0x07>;
			dram_mr16 = <0x00>;
			dram_mr17 = <0x00>;
			dram_mr22 = <0x26>;
			dram_tpr0 = <0x6060606>;
			dram_tpr1 = <0x4040404>;
			dram_tpr2 = <0x00>;
			dram_tpr3 = <0x00>;
			dram_tpr6 = <0x48010101>;
			dram_tpr10 = <0x273333>;
			dram_tpr11 = <0x241f1923>;
			dram_tpr12 = <0x14151313>;
			dram_tpr13 = <0x81d20>;
			dram_tpr14 = <0x2023211f>;
		};

		dram_para8 {
			device_type = "dram_para8";
			dram_clk = <0x240>;
			dram_type = <0x07>;
			dram_dx_odt = <0x6060606>;
			dram_dx_dri = <0xc0c0c0c>;
			dram_ca_dri = <0x1919>;
			dram_para0 = <0x17171412>;
			dram_para1 = <0x30fa>;
			dram_para2 = <0x00>;
			dram_mr0 = <0x00>;
			dram_mr1 = <0xc3>;
			dram_mr2 = <0x06>;
			dram_mr3 = <0x02>;
			dram_mr4 = <0x00>;
			dram_mr5 = <0x00>;
			dram_mr6 = <0x00>;
			dram_mr11 = <0x00>;
			dram_mr12 = <0x00>;
			dram_mr13 = <0x00>;
			dram_mr14 = <0x00>;
			dram_mr16 = <0x00>;
			dram_mr17 = <0x1e1a1a17>;
			dram_mr22 = <0x2a28282b>;
			dram_tpr0 = <0x1616181e>;
			dram_tpr1 = <0x1c1a1a16>;
			dram_tpr2 = <0x18181818>;
			dram_tpr3 = <0x800000>;
			dram_tpr6 = <0x2fb88080>;
			dram_tpr10 = <0x2fbbcf>;
			dram_tpr11 = <0x1415110a>;
			dram_tpr12 = <0x14141616>;
			dram_tpr13 = <0x2008060>;
			dram_tpr14 = <0x25242629>;
		};

		dram_para9 {
			device_type = "dram_para9";
			dram_clk = <0x240>;
			dram_type = <0x07>;
			dram_dx_odt = <0x6060606>;
			dram_dx_dri = <0xc0c0c0c>;
			dram_ca_dri = <0x1919>;
			dram_para0 = <0x17171412>;
			dram_para1 = <0x30fa>;
			dram_para2 = <0x00>;
			dram_mr0 = <0x00>;
			dram_mr1 = <0xc3>;
			dram_mr2 = <0x06>;
			dram_mr3 = <0x02>;
			dram_mr4 = <0x00>;
			dram_mr5 = <0x00>;
			dram_mr6 = <0x00>;
			dram_mr11 = <0x00>;
			dram_mr12 = <0x00>;
			dram_mr13 = <0x00>;
			dram_mr14 = <0x00>;
			dram_mr16 = <0x00>;
			dram_mr17 = <0x1e1a1a17>;
			dram_mr22 = <0x2a28282b>;
			dram_tpr0 = <0x1616181e>;
			dram_tpr1 = <0x1c1a1a16>;
			dram_tpr2 = <0x18181818>;
			dram_tpr3 = <0x800000>;
			dram_tpr6 = <0x2fb88080>;
			dram_tpr10 = <0x2fbbcf>;
			dram_tpr11 = <0x1415110a>;
			dram_tpr12 = <0x14141616>;
			dram_tpr13 = <0x2008060>;
			dram_tpr14 = <0x25242629>;
		};

		dram_para10 {
			device_type = "dram_para10";
			dram_clk = <0x240>;
			dram_type = <0x07>;
			dram_dx_odt = <0x6060606>;
			dram_dx_dri = <0xc0c0c0c>;
			dram_ca_dri = <0x1919>;
			dram_para0 = <0x17171412>;
			dram_para1 = <0x30fa>;
			dram_para2 = <0x00>;
			dram_mr0 = <0x00>;
			dram_mr1 = <0xc3>;
			dram_mr2 = <0x06>;
			dram_mr3 = <0x02>;
			dram_mr4 = <0x00>;
			dram_mr5 = <0x00>;
			dram_mr6 = <0x00>;
			dram_mr11 = <0x00>;
			dram_mr12 = <0x00>;
			dram_mr13 = <0x00>;
			dram_mr14 = <0x00>;
			dram_mr16 = <0x00>;
			dram_mr17 = <0x1e1a1a17>;
			dram_mr22 = <0x2a28282b>;
			dram_tpr0 = <0x1616181e>;
			dram_tpr1 = <0x1c1a1a16>;
			dram_tpr2 = <0x18181818>;
			dram_tpr3 = <0x800000>;
			dram_tpr6 = <0x2fb88080>;
			dram_tpr10 = <0x2fbbcf>;
			dram_tpr11 = <0x1415110a>;
			dram_tpr12 = <0x14141616>;
			dram_tpr13 = <0x2008060>;
			dram_tpr14 = <0x25242629>;
		};

		dram_para11 {
			device_type = "dram_para11";
			dram_clk = <0x240>;
			dram_type = <0x07>;
			dram_dx_odt = <0x6060606>;
			dram_dx_dri = <0xc0c0c0c>;
			dram_ca_dri = <0x1919>;
			dram_para0 = <0x17171412>;
			dram_para1 = <0x30fa>;
			dram_para2 = <0x00>;
			dram_mr0 = <0x00>;
			dram_mr1 = <0xc3>;
			dram_mr2 = <0x06>;
			dram_mr3 = <0x02>;
			dram_mr4 = <0x00>;
			dram_mr5 = <0x00>;
			dram_mr6 = <0x00>;
			dram_mr11 = <0x00>;
			dram_mr12 = <0x00>;
			dram_mr13 = <0x00>;
			dram_mr14 = <0x00>;
			dram_mr16 = <0x00>;
			dram_mr17 = <0x1e1a1a17>;
			dram_mr22 = <0x2a28282b>;
			dram_tpr0 = <0x1616181e>;
			dram_tpr1 = <0x1c1a1a16>;
			dram_tpr2 = <0x18181818>;
			dram_tpr3 = <0x800000>;
			dram_tpr6 = <0x2fb88080>;
			dram_tpr10 = <0x2fbbcf>;
			dram_tpr11 = <0x1415110a>;
			dram_tpr12 = <0x14141616>;
			dram_tpr13 = <0x2008060>;
			dram_tpr14 = <0x25242629>;
		};

		dram_para12 {
			device_type = "dram_para12";
			dram_clk = <0x240>;
			dram_type = <0x07>;
			dram_dx_odt = <0x6060606>;
			dram_dx_dri = <0xc0c0c0c>;
			dram_ca_dri = <0x1919>;
			dram_para0 = <0x17171412>;
			dram_para1 = <0x30fa>;
			dram_para2 = <0x00>;
			dram_mr0 = <0x00>;
			dram_mr1 = <0xc3>;
			dram_mr2 = <0x06>;
			dram_mr3 = <0x02>;
			dram_mr4 = <0x00>;
			dram_mr5 = <0x00>;
			dram_mr6 = <0x00>;
			dram_mr11 = <0x00>;
			dram_mr12 = <0x00>;
			dram_mr13 = <0x00>;
			dram_mr14 = <0x00>;
			dram_mr16 = <0x00>;
			dram_mr17 = <0x1e1a1a17>;
			dram_mr22 = <0x2a28282b>;
			dram_tpr0 = <0x1616181e>;
			dram_tpr1 = <0x1c1a1a16>;
			dram_tpr2 = <0x18181818>;
			dram_tpr3 = <0x800000>;
			dram_tpr6 = <0x2fb88080>;
			dram_tpr10 = <0x2fbbcf>;
			dram_tpr11 = <0x1415110a>;
			dram_tpr12 = <0x14141616>;
			dram_tpr13 = <0x2008060>;
			dram_tpr14 = <0x25242629>;
		};

		dram_para13 {
			device_type = "dram_para13";
			dram_clk = <0x240>;
			dram_type = <0x07>;
			dram_dx_odt = <0x6060606>;
			dram_dx_dri = <0xc0c0c0c>;
			dram_ca_dri = <0x1919>;
			dram_para0 = <0x17171412>;
			dram_para1 = <0x30fa>;
			dram_para2 = <0x00>;
			dram_mr0 = <0x00>;
			dram_mr1 = <0xc3>;
			dram_mr2 = <0x06>;
			dram_mr3 = <0x02>;
			dram_mr4 = <0x00>;
			dram_mr5 = <0x00>;
			dram_mr6 = <0x00>;
			dram_mr11 = <0x00>;
			dram_mr12 = <0x00>;
			dram_mr13 = <0x00>;
			dram_mr14 = <0x00>;
			dram_mr16 = <0x00>;
			dram_mr17 = <0x1e1a1a17>;
			dram_mr22 = <0x2a28282b>;
			dram_tpr0 = <0x1616181e>;
			dram_tpr1 = <0x1c1a1a16>;
			dram_tpr2 = <0x18181818>;
			dram_tpr3 = <0x800000>;
			dram_tpr6 = <0x2fb88080>;
			dram_tpr10 = <0x2fbbcf>;
			dram_tpr11 = <0x1415110a>;
			dram_tpr12 = <0x14141616>;
			dram_tpr13 = <0x2008060>;
			dram_tpr14 = <0x25242629>;
		};

		dram_para14 {
			device_type = "dram_para14";
			dram_clk = <0x318>;
			dram_type = <0x08>;
			dram_dx_odt = <0x7070707>;
			dram_dx_dri = <0xd0d0d0d>;
			dram_ca_dri = <0xe0e>;
			dram_para0 = <0xd0a050c>;
			dram_para1 = <0x30ea>;
			dram_para2 = <0x1000>;
			dram_mr0 = <0x00>;
			dram_mr1 = <0x34>;
			dram_mr2 = <0x1b>;
			dram_mr3 = <0x33>;
			dram_mr4 = <0x03>;
			dram_mr5 = <0x00>;
			dram_mr6 = <0x00>;
			dram_mr11 = <0x04>;
			dram_mr12 = <0x72>;
			dram_mr13 = <0x00>;
			dram_mr14 = <0x07>;
			dram_mr16 = <0x00>;
			dram_mr17 = <0x00>;
			dram_mr22 = <0x26>;
			dram_tpr0 = <0x6060606>;
			dram_tpr1 = <0x4040404>;
			dram_tpr2 = <0x00>;
			dram_tpr3 = <0x00>;
			dram_tpr6 = <0x48010101>;
			dram_tpr10 = <0x273333>;
			dram_tpr11 = <0x241f1923>;
			dram_tpr12 = <0x14151313>;
			dram_tpr13 = <0x81d20>;
			dram_tpr14 = <0x2023211f>;
		};

		dram_para15 {
			device_type = "dram_para15";
			dram_clk = <0x318>;
			dram_type = <0x08>;
			dram_dx_odt = <0x7070707>;
			dram_dx_dri = <0xd0d0d0d>;
			dram_ca_dri = <0xe0e>;
			dram_para0 = <0xd0a050c>;
			dram_para1 = <0x30ea>;
			dram_para2 = <0x1000>;
			dram_mr0 = <0x00>;
			dram_mr1 = <0x34>;
			dram_mr2 = <0x1b>;
			dram_mr3 = <0x33>;
			dram_mr4 = <0x03>;
			dram_mr5 = <0x00>;
			dram_mr6 = <0x00>;
			dram_mr11 = <0x04>;
			dram_mr12 = <0x72>;
			dram_mr13 = <0x00>;
			dram_mr14 = <0x07>;
			dram_mr16 = <0x00>;
			dram_mr17 = <0x00>;
			dram_mr22 = <0x26>;
			dram_tpr0 = <0x6060606>;
			dram_tpr1 = <0x4040404>;
			dram_tpr2 = <0x00>;
			dram_tpr3 = <0x00>;
			dram_tpr6 = <0x48010101>;
			dram_tpr10 = <0x273333>;
			dram_tpr11 = <0x241f1923>;
			dram_tpr12 = <0x14151313>;
			dram_tpr13 = <0x81d20>;
			dram_tpr14 = <0x2023211f>;
		};

		charger0 {
			device_type = "charger0";
			pmu_safe_vol = <0xce4>;
			ntc_cur = <0x32>;
			safe_temp_H = <0x258>;
			safe_temp_L = <0x00>;
			pmu_bat_temp_para1 = <0x11ef>;
			pmu_bat_temp_para2 = <0xadd>;
			pmu_bat_temp_para3 = <0x88e>;
			pmu_bat_temp_para4 = <0x6ca>;
			pmu_bat_temp_para5 = <0x56e>;
			pmu_bat_temp_para6 = <0x45e>;
			pmu_bat_temp_para7 = <0x38a>;
			pmu_bat_temp_para8 = <0x25e>;
			pmu_bat_temp_para9 = <0x19f>;
			pmu_bat_temp_para10 = <0x122>;
			pmu_bat_temp_para11 = <0xf4>;
			pmu_bat_temp_para12 = <0xce>;
			pmu_bat_temp_para13 = <0xaf>;
			pmu_bat_temp_para14 = <0x96>;
			pmu_bat_temp_para15 = <0x6e>;
			pmu_bat_temp_para16 = <0x53>;
		};

		partitions {
			device_type = "partitions";

			bootloader {
				device_type = "bootloader";
				offset = <0x400>;
				size = <0xc000>;
			};

			env {
				device_type = "env";
				offset = <0xc400>;
				size = <0x400>;
			};

			env-redund {
				device_type = "env-redund";
				offset = <0xc800>;
				size = <0x400>;
			};

			boot {
				device_type = "boot";
				offset = <0xcc00>;
				size = <0xc000>;
			};

			rootfs {
				device_type = "rootfs";
				offset = <0x18c00>;
				size = <0x118000>;
			};

			rootfs_data {
				device_type = "rootfs_data";
				offset = <0x130c00>;
				size = <0x400000>;
			};

			private {
				device_type = "private";
				offset = <0x530c00>;
				size = <0x400>;
			};

			recovery {
				device_type = "recovery";
				offset = <0x531000>;
				size = <0x8000>;
			};

			pstore {
				device_type = "pstore";
				offset = <0x539000>;
				size = <0x400>;
			};

			UDISK {
				device_type = "UDISK";
				offset = <0x539400>;
				size = <0x00>;
			};
		};
	};



	firmware {

		android {
			compatible = "android,firmware";
			boot_devices = "soc/sdc0,soc/sdc2,soc";

			vbmeta {
				compatible = "android,vbmeta";
				parts = "vbmeta,vbmeta_system,vbmeta_vendor,boot,super,recovery";
			};
		};

		optee {
			compatible = "linaro,optee-tz";
			method = "smc";
		};
	};

	cpus {
		#address-cells = <0x02>;
		#size-cells = <0x00>;

		cpu0: cpu@0 {
			device_type = "cpu";
			compatible = "arm,cortex-a53\0arm,armv8";
			reg = <0x00 0x00>;
			enable-method = "psci";
			clocks = <&clk_pll_cpu>;
			clock-latency = <0x1e8480>;
			clock-frequency = <0x4ead9a00>;
			dynamic-power-coefficient = <0xbe>;
			operating-points-v2 = <&cpu_opp_l_table>;
			cpu-idle-states = <&CPU_SLEEP_0 &CLUSTER_SLEEP_0>;
			#cooling-cells = <0x02>;
			cpu-supply = <&reg_tcs0>;
			phandle = <0xf2>;
		};

		cpu@1 {
			device_type = "cpu";
			compatible = "arm,cortex-a53\0arm,armv8";
			reg = <0x00 0x01>;
			enable-method = "psci";
			clocks = <&clk_pll_cpu>;
			clock-frequency = <0x4ead9a00>;
			operating-points-v2 = <&cpu_opp_l_table>;
			cpu-idle-states = <&CPU_SLEEP_0 &CLUSTER_SLEEP_0>;
			#cooling-cells = <0x02>;
		};

		cpu@2 {
			device_type = "cpu";
			compatible = "arm,cortex-a53\0arm,armv8";
			reg = <0x00 0x02>;
			enable-method = "psci";
			clocks = <&clk_pll_cpu>;
			clock-frequency = <0x4ead9a00>;
			operating-points-v2 = <&cpu_opp_l_table>;
			cpu-idle-states = <&CPU_SLEEP_0 &CLUSTER_SLEEP_0>;
			#cooling-cells = <0x02>;
		};

		cpu@3 {
			device_type = "cpu";
			compatible = "arm,cortex-a53\0arm,armv8";
			reg = <0x00 0x03>;
			enable-method = "psci";
			clocks = <&clk_pll_cpu>;
			clock-frequency = <0x4ead9a00>;
			operating-points-v2 = <&cpu_opp_l_table>;
			cpu-idle-states = <&CPU_SLEEP_0 &CLUSTER_SLEEP_0>;
			#cooling-cells = <0x02>;
		};

		idle-states {
			entry-method = "arm,psci";

			CPU_SLEEP_0: cpu-sleep-0 {
				compatible = "arm,idle-state";
				arm,psci-suspend-param = <0x10000>;
				entry-latency-us = <0x2e>;
				exit-latency-us = <0x3b>;
				min-residency-us = <0xdf2>;
				local-timer-stop;
				phandle = <0x100>;
			};

			CLUSTER_SLEEP_0: cluster-sleep-0 {
				compatible = "arm,idle-state";
				arm,psci-suspend-param = <0x1010000>;
				entry-latency-us = <0x2f>;
				exit-latency-us = <0x4a>;
				min-residency-us = <0x1388>;
				local-timer-stop;
				phandle = <0x101>;
			};
		};
	};

	cpu_opp_l_table: opp_l_table {
		compatible = "allwinner,sun50i-operating-points";
		nvmem-cells = <&speedbin_efuse &cpubin_efuse>;
		nvmem-cell-names = "speed\0bin";
		opp-shared;
		phandle = <0xff>;

		opp@408000000 {
			opp-hz = <0x00 0x18519600>;
			clock-latency-ns = <0x3b9b0>;
			opp-microvolt-a0 = <0xdbba0>;
			opp-microvolt-a1 = <0xdbba0>;
			opp-microvolt-a2 = <0xdbba0>;
			opp-microvolt-a3 = <0xe4e1c 0xe4e1c 0xe57e0>;
			opp-microvolt-a4 = <0xe4e1c 0xe4e1c 0xe57e0>;
			opp-microvolt-a5 = <0xe09c0 0xe09c0 0xe1d48>;
			opp-microvolt-a6 = <0xe09c0 0xe09c0 0xe1d48>;
			opp-microvolt-b0 = <0xdbba0>;
			opp-microvolt-b1 = <0xdbba0>;
			opp-microvolt-b2 = <0xe4e1c 0xe4e1c 0xe57e0>;
			opp-microvolt-b3 = <0xe09c0 0xe09c0 0xe1d48>;
			opp-microvolt-c0 = <0xdbba0>;
		};

		opp@600000000 {
			opp-hz = <0x00 0x23c34600>;
			clock-latency-ns = <0x3b9b0>;
			opp-microvolt-a0 = <0xdbba0>;
			opp-microvolt-a1 = <0xdbba0>;
			opp-microvolt-a2 = <0xdbba0>;
			opp-microvolt-a3 = <0xe4e1c 0xe4e1c 0xe57e0>;
			opp-microvolt-a4 = <0xe4e1c 0xe4e1c 0xe57e0>;
			opp-microvolt-a5 = <0xe09c0 0xe09c0 0xe1d48>;
			opp-microvolt-a6 = <0xe09c0 0xe09c0 0xe1d48>;
			opp-microvolt-b0 = <0xdbba0>;
			opp-microvolt-b1 = <0xdbba0>;
			opp-microvolt-b2 = <0xe4e1c 0xe4e1c 0xe57e0>;
			opp-microvolt-b3 = <0xe09c0 0xe09c0 0xe1d48>;
			opp-microvolt-c0 = <0xdbba0>;
		};

		opp@816000000 {
			opp-hz = <0x00 0x30a32c00>;
			clock-latency-ns = <0x3b9b0>;
			opp-microvolt-a0 = <0xe4e1c 0xe4e1c 0xe57e0>;
			opp-microvolt-a1 = <0xdbba0>;
			opp-microvolt-a2 = <0xdbba0>;
			opp-microvolt-a3 = <0xe4e1c 0xe4e1c 0xe57e0>;
			opp-microvolt-a4 = <0xe4e1c 0xe4e1c 0xe57e0>;
			opp-microvolt-a5 = <0xe09c0 0xe09c0 0xe1d48>;
			opp-microvolt-a6 = <0xe09c0 0xe09c0 0xe1d48>;
			opp-microvolt-b0 = <0xdbba0>;
			opp-microvolt-b1 = <0xdbba0>;
			opp-microvolt-b2 = <0xe4e1c 0xe4e1c 0xe57e0>;
			opp-microvolt-b3 = <0xe09c0 0xe09c0 0xe1d48>;
			opp-microvolt-c0 = <0xdbba0>;
		};

		opp@1008000000 {
			opp-hz = <0x00 0x3c14dc00>;
			clock-latency-ns = <0x3b9b0>;
			opp-microvolt-a0 = <0xf9060 0xf9060 0xfa3e8>;
			opp-microvolt-a1 = <0xee098 0xee098 0xef420>;
			opp-microvolt-a2 = <0xe7ef0>;
			opp-microvolt-a3 = <0xf9060 0xf9060 0xfa3e8>;
			opp-microvolt-a4 = <0xea600 0xea600 0xeafc4>;
			opp-microvolt-a5 = <0xe4e1c 0xe4e1c 0xe57e0>;
			opp-microvolt-a6 = <0xe4e1c 0xe4e1c 0xe57e0>;
			opp-microvolt-b0 = <0xee098 0xee098 0xef420>;
			opp-microvolt-b1 = <0xe7ef0>;
			opp-microvolt-b2 = <0xea600 0xea600 0xeafc4>;
			opp-microvolt-b3 = <0xe4e1c 0xe4e1c 0xe57e0>;
			opp-microvolt-c0 = <0xdbba0>;
		};

		opp@1200000000 {
			opp-hz = <0x00 0x47868c00>;
			clock-latency-ns = <0x3b9b0>;
			opp-microvolt-a0 = <0x10c8e0>;
			opp-microvolt-a1 = <0xf9060 0xf9060 0xfa3e8>;
			opp-microvolt-a2 = <0xf4240>;
			opp-microvolt-a3 = <0x10c8e0>;
			opp-microvolt-a4 = <0xee098 0xee098 0xef420>;
			opp-microvolt-a5 = <0xea600 0xea600 0xeafc4>;
			opp-microvolt-a6 = <0xea600 0xea600 0xeafc4>;
			opp-microvolt-b0 = <0xf9060 0xf9060 0xfa3e8>;
			opp-microvolt-b1 = <0xf4240>;
			opp-microvolt-b2 = <0xee098 0xee098 0xef420>;
			opp-microvolt-b3 = <0xea600 0xea600 0xeafc4>;
			opp-microvolt-c0 = <0xe4e1c 0xe4e1c 0xe57e0>;
		};

		opp@1320000000 {
			opp-hz = <0x00 0x4ead9a00>;
			clock-latency-ns = <0x3b9b0>;
			opp-microvolt-a0 = <0x11b340 0x11b340 0x11bd04>;
			opp-microvolt-a1 = <0x102ca0 0x102ca0 0x103664>;
			opp-microvolt-a2 = <0xfa3e8 0xfa3e8 0xfb770>;
			opp-microvolt-a3 = <0x11b340 0x11b340 0x11bd04>;
			opp-microvolt-a4 = <0xf9060 0xf9060 0xfa3e8>;
			opp-microvolt-a5 = <0xf4240>;
			opp-microvolt-a6 = <0xf4240>;
			opp-microvolt-b0 = <0x102ca0 0x102ca0 0x103664>;
			opp-microvolt-b1 = <0xfa3e8 0xfa3e8 0xfb770>;
			opp-microvolt-b2 = <0xf9060 0xf9060 0xfa3e8>;
			opp-microvolt-b3 = <0xf4240>;
		};

		opp@1416000000 {
			opp-hz = <0x00 0x54667200>;
			clock-latency-ns = <0x3b9b0>;
			opp-microvolt-b0 = <0x10c8e0>;
			opp-microvolt-b1 = <0x1053b0 0x1053b0 0x106738>;
			opp-microvolt-b2 = <0x102ca0 0x102ca0 0x103664>;
			opp-microvolt-b3 = <0xfd4bc 0xfd4bc 0xfde80>;
			opp-microvolt-c0 = <0xf9060 0xf9060 0xfa3e8>;
		};

		opp@1464000000 {
			opp-hz = <0x00 0x5742de00>;
			clock-latency-ns = <0x3b9b0>;
			opp-microvolt-a0 = <0x120160 0x120160 0x121eac>;
			opp-microvolt-a1 = <0x120160 0x120160 0x121eac>;
			opp-microvolt-a2 = <0x112a88 0x112a88 0x113e10>;
			opp-microvolt-a3 = <0x120160 0x120160 0x121eac>;
			opp-microvolt-a4 = <0x10c8e0>;
			opp-microvolt-a5 = <0x106738 0x106738 0x107ac0>;
			opp-microvolt-a6 = <0x106738 0x106738 0x107ac0>;
		};

		opp@1512000000 {
			opp-hz = <0x00 0x5a1f4a00>;
			clock-latency-ns = <0x3b9b0>;
			opp-microvolt-b0 = <0x120160 0x120160 0x121eac>;
			opp-microvolt-b1 = <0x113e10 0x113e10 0x116520>;
			opp-microvolt-b2 = <0x10c8e0>;
			opp-microvolt-b3 = <0x106738 0x106738 0x107ac0>;
		};

		opp@1608000000 {
			opp-hz = <0x00 0x5fd82200>;
			clock-latency-ns = <0x3b9b0>;
			opp-microvolt-c0 = <0x10c8e0>;
		};

		opp@1800000000 {
			opp-hz = <0x00 0x6b49d200>;
			clock-latency-ns = <0x3b9b0>;
			opp-microvolt-c0 = <0x120160 0x120160 0x121eac>;
		};

		opp@2000000000 {
			opp-hz = <0x00 0x77359400>;
			clock-latency-ns = <0x3b9b0>;
			opp-microvolt-c0 = <0x1312d0 0x1312d0 0x13301c>;
		};
	};

	psci {
		compatible = "arm,psci-1.0";
		method = "smc";
	};



	sram_ctrl {
		device_type = "sram_ctrl";
		compatible = "allwinner,sram_ctrl";
		reg = <0x00 0x3000000 0x00 0x100>;
	};





	ion {
		compatible = "allwinner,sunxi-ion";

		heap_sys_user@0 {
			compatible = "allwinner,sys_user";
			heap-name = "sys_user";
			heap-id = <0x00>;
			heap-base = <0x00>;
			heap-size = <0x00>;
			heap-type = "ion_system";
		};

		heap_cma@0 {
			compatible = "allwinner,cma";
			heap-name = "cma";
			heap-id = <0x04>;
			heap-base = <0x00>;
			heap-size = <0x00>;
			heap-type = "ion_cma";
		};

		heap_secure@0 {
			compatible = "allwinner,secure";
			heap-name = "secure";
			heap-id = <0x06>;
			heap-base = <0x00>;
			heap-size = <0x00>;
			heap-type = "ion_secure";
		};
	};



	gic: interrupt-controller@03020000 {
		compatible = "arm,cortex-a15-gic\0arm,cortex-a9-gic";
		#interrupt-cells = <0x03>;
		#address-cells = <0x00>;
		device_type = "gic";
		interrupt-controller;
		reg = <0x00 0x3021000 0x00 0x1000 0x00 0x3022000 0x00 0x2000 0x00 0x3024000 0x00 0x2000 0x00 0x3026000 0x00 0x2000>;
		interrupts = <0x01 0x09 0xf04>;
		interrupt-parent = <&gic>;
		phandle = <0xa8>;
	};

	wakeupgen: interrupt-controller@0 {
		compatible = "allwinner,sunxi-wakeupgen";
		interrupt-controller;
		#interrupt-cells = <0x03>;
		interrupt-parent = <&gic>;
		phandle = <0x01>;
	};

	nmi_intc: intc-nmi@07010320 {
		compatible = "allwinner,sun8i-nmi";
		interrupt-parent = <&gic>;
		#interrupt-cells = <0x02>;
		#address-cells = <0x00>;
		interrupt-controller;
		reg = <0x00 0x7010320 0x00 0x0c>;
		interrupts = <0x00 0x67 0x04>;
		phandle = <0x43>;
	};

	sid: sunxi-sid@03006000 {
		compatible = "allwinner,sunxi-sid";
		device_type = "sid";
		reg = <0x00 0x3006000 0x00 0x1000>;
		phandle = <0x1bc>;
	};

	sunxi-sid-ng@03006000 {
		compatible = "allwinner,sun50iw10p1-sid";
		reg = <0x00 0x3006000 0x00 0x1000>;
		#address-cells = <0x01>;
		#size-cells = <0x01>;

		speedbin_efuse: speed@00 {
			reg = <0x00 0x02>;
			phandle = <0x103>;
		};

		ths_calib: calib@14 {
			reg = <0x14 0x08>;
			phandle = <0xef>;
		};

		cpubin_efuse: calib@1c {
			reg = <0x1c 0x02>;
			phandle = <0x104>;
		};
	};

	chipid: sunxi-chipid@03006200 {
		compatible = "allwinner,sunxi-chipid";
		device_type = "chipid";
		reg = <0x00 0x3006200 0x00 0x200>;
		phandle = <0x1bd>;
	};

	timer_arch {
		compatible = "arm,armv8-timer";
		interrupts = <0x01 0x0d 0xf08 0x01 0x0e 0xf08 0x01 0x0b 0xf08 0x01 0x0a 0xf08>;
		clock-frequency = <0x16e3600>;
		interrupt-parent = <&gic>;
		arm,no-tick-in-suspend;
	};

	pd_gpu: gpu-power-domain@07001000 {
		compatible = "allwinner,gpu-pd\0syscon";
		reg = <0x00 0x7001000 0x00 0x40>;
		interrupts = <0x00 0x77 0x04>;
		interrupt-names = "ppu-irq";
		clocks = <&clk_ppu>;
		clock-names = "ppu";
		#power-domain-cells = <0x00>;
		phandle = <0x109>;
	};




	mmu_aw: iommu@030f0000 {
		compatible = "allwinner,sunxi-iommu";
		reg = <0x00 0x30f0000 0x00 0x1000>;
		interrupts = <0x00 0x42 0x04>;
		interrupt-names = "iommu-irq";
		clocks = <&clk_iommu>;
		clock-names = "iommu";
		#iommu-cells = <0x02>;
		status = "okay";
		phandle = <0x26>;
	};

	gpu: gpu@0x01800000 {
		device_type = "gpu";
		compatible = "img,gpu";
		reg = <0x00 0x1800000 0x00 0x80000>;
		interrupts = <0x00 0x61 0x04>;
		interrupt-names = "IRQGPU";
		clocks = <&clk_pll_gpu &clk_gpu>;
		clock-names = "clk_parent\0clk_mali";
		power-domains = <&pd_gpu>;
		gpu_idle = <0x01>;
		dvfs_status = <0x01>;
		pll_rate = <0xaae60>;
		independent_power = <0x00>;
		operating-points = <0xaae60 0x10c8e0 0x61698 0xe7ef0 0x37aa0 0xe7ef0>;
		phandle = <0x1bf>;
	};










	axp2202_parameter: axp2202-parameter {
		select = "battery-model";
		phandle = <0x47>;

		battery-model {
			parameter = <0x1f54000 0x1b1e280f 0xc1e3202 0x14050a04 0x74fbc80d 0x431036fb 0x4601ea0d 0x2a063605 0xf40ab50f 0x420ee609 0x9a0e420e 0x3b042d04 0x2309180e 0x90e0408 0xf70dda0d 0xd003bb03 0x9d087f0d 0x6a0d5507 0xc2572b27 0x1e0d1408 0xc5987e66 0x4e44381a 0x120af600 0xf600f6 0xfb0000 0xfb0000fb 0xf600 0xf600f6 0xfb0000 0xfb0000fb 0xf600 0xf600f6>;
		};
	};

};
